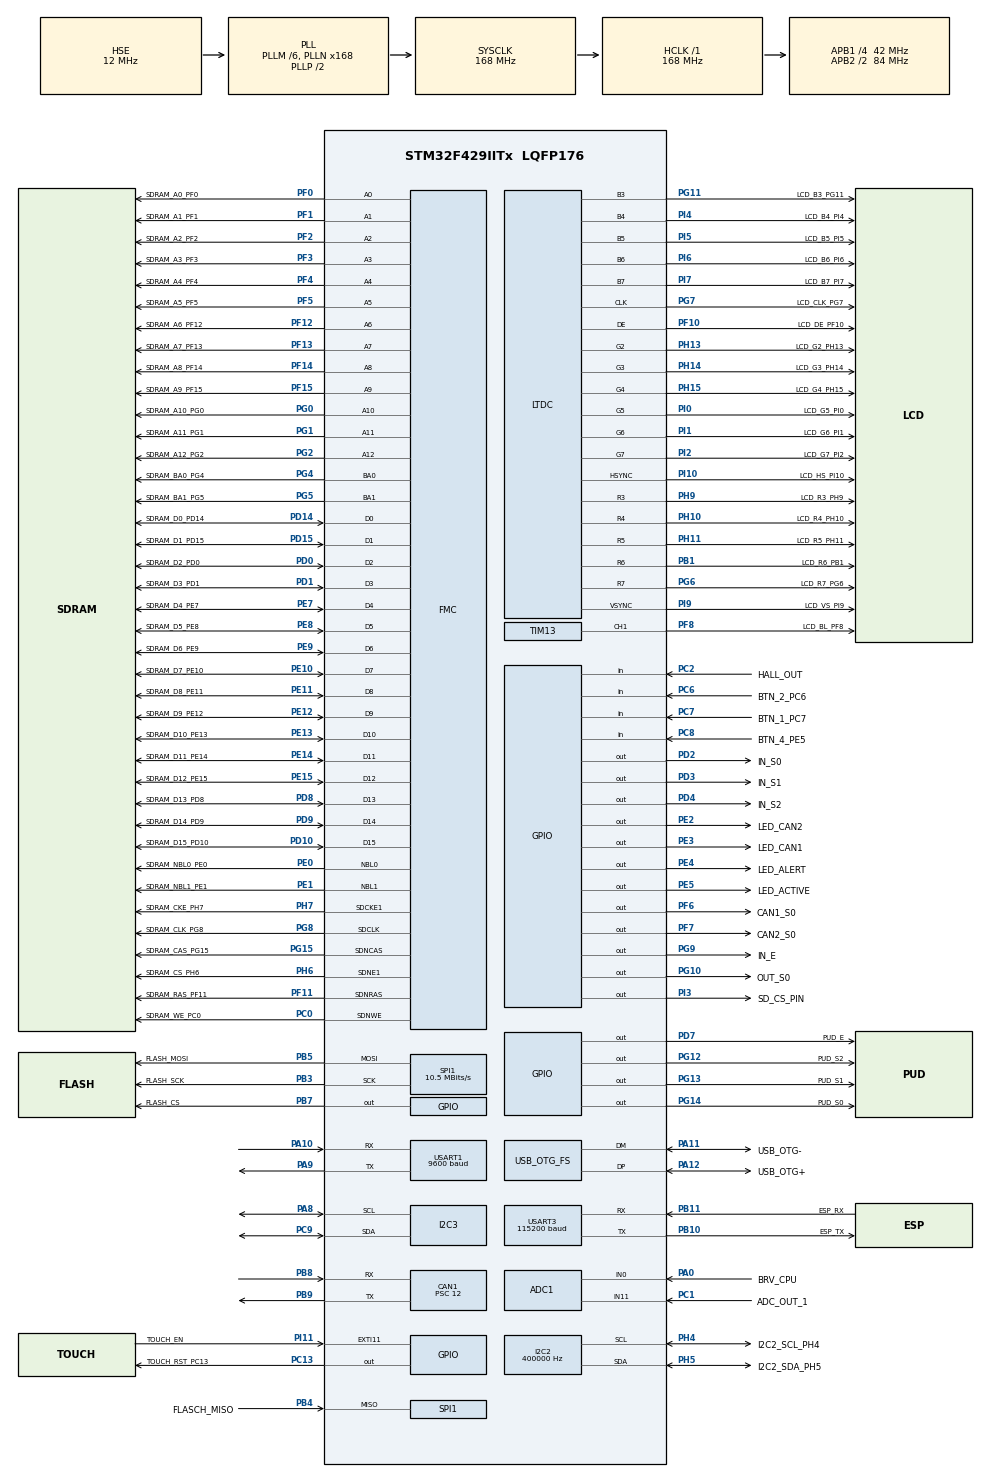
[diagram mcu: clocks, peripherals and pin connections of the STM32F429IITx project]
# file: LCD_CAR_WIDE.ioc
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ADC1.Channel-0\#ChannelRegularConversion=ADC_CHANNEL_11
ADC1.NbrOfConversionFlag=1
ADC1.Rank-0\#ChannelRegularConversion=1
ADC1.SamplingTime-0\#ChannelRegularConversion=ADC_SAMPLETIME_3CYCLES
ADC1.master=1
CAN1.BS1=CAN_BS1_4TQ
CAN1.BS2=CAN_BS2_2TQ
CAN1.CalculateBaudRate=500000
CAN1.CalculateTimeBit=2000
CAN1.CalculateTimeQuantum=285.7142857142857
CAN1.Prescaler=12
DMA2D.ColorMode=DMA2D_OUTPUT_RGB565
DMA2D.Mode=DMA2D_M2M
Dma.Request0=USART3_RX
Dma.Request1=USART3_TX
Dma.USART3_RX.0.Direction=DMA_PERIPH_TO_MEMORY
Dma.USART3_RX.0.FIFOMode=DMA_FIFOMODE_DISABLE
Dma.USART3_RX.0.Instance=DMA1_Stream1
Dma.USART3_RX.0.MemDataAlignment=DMA_MDATAALIGN_BYTE
Dma.USART3_RX.0.MemInc=DMA_MINC_ENABLE
Dma.USART3_RX.0.Mode=DMA_NORMAL
Dma.USART3_RX.0.PeriphDataAlignment=DMA_PDATAALIGN_BYTE
Dma.USART3_RX.0.PeriphInc=DMA_PINC_DISABLE
Dma.USART3_RX.0.Priority=DMA_PRIORITY_LOW
Dma.USART3_TX.1.Direction=DMA_MEMORY_TO_PERIPH
Dma.USART3_TX.1.FIFOMode=DMA_FIFOMODE_DISABLE
Dma.USART3_TX.1.Instance=DMA1_Stream3
Dma.USART3_TX.1.MemDataAlignment=DMA_MDATAALIGN_BYTE
Dma.USART3_TX.1.MemInc=DMA_MINC_ENABLE
Dma.USART3_TX.1.Mode=DMA_NORMAL
Dma.USART3_TX.1.PeriphDataAlignment=DMA_PDATAALIGN_BYTE
Dma.USART3_TX.1.PeriphInc=DMA_PINC_DISABLE
Dma.USART3_TX.1.Priority=DMA_PRIORITY_LOW
FMC.CASLatency1=FMC_SDRAM_CAS_LATENCY_3
FMC.ColumnBitsNumber1=FMC_SDRAM_COLUMN_BITS_NUM_9
FMC.ExitSelfRefreshDelay1=8
FMC.LoadToActiveDelay1=2
FMC.RCDDelay1=2
FMC.RPDelay1=2
FMC.RPDelay2=2
FMC.ReadBurst1=FMC_SDRAM_RBURST_ENABLE
FMC.ReadPipeDelay1=FMC_SDRAM_RPIPE_DELAY_1
FMC.ReadPipeDelay2=FMC_SDRAM_RPIPE_DELAY_1
FMC.RowCycleDelay1=7
FMC.RowCycleDelay2=7
FMC.SDClockPeriod1=FMC_SDRAM_CLOCK_PERIOD_2
FMC.SDClockPeriod2=FMC_SDRAM_CLOCK_PERIOD_2
FMC.SelfRefreshTime1=4
FMC.WriteRecoveryTime1=5
FREERTOS.Queues01=jsonQueue,6,512,1,Dynamic,NULL,NULL
FREERTOS.Tasks01=START_Task,24,128,Start_START_Task,Default,NULL,Dynamic,NULL,NULL;TouchGFXTask,40,4096,TouchGFX_Task,As weak,NULL,Dynamic,NULL,NULL;BRIGHTNESS_Task,8,1024,Start_BRIGHTNESS_Task,Default,NULL,Dynamic,NULL,NULL;nmea,8,1024,Start_nmea,Default,NULL,Dynamic,NULL,NULL;Ind_OIL,8,128,Start_OIL,Default,NULL,Dynamic,NULL,NULL;Ind_FUEL,8,128,Start_Ind_FUEL,Default,NULL,Dynamic,NULL,NULL;Ind_BATT,8,128,Start_IndBATT,Default,NULL,Dynamic,NULL,NULL;Ind_ECT,8,128,Start_Ind_ECT,Default,NULL,Dynamic,NULL,NULL;other,8,128,Start_other,Default,NULL,Dynamic,NULL,NULL;RPM_10,8,4096,Start_RMP_10,Default,&rpmWindowSize,Dynamic,NULL,NULL;FUELUSED_11,8,4096,Start_FUELUSED_11,Default,&windows,Dynamic,NULL,NULL;UART_Task,8,4096,Start_UART_Task,Default,NULL,Dynamic,NULL,NULL;MotohoursTask,8,1024,Start_MotohoursTask,Default,NULL,Dynamic,NULL,NULL;Button_R_Task,8,1024,Start_R_Buttan_Task14,Default,NULL,Dynamic,NULL,NULL;Button_L_Task,8,1024,Start_Buttan_L_Task,Default,NULL,Dynamic,NULL,NULL;JSON_Parse_Task,8,1024,Start_JSON_Parse_Task,Default,NULL,Dynamic,NULL,NULL
FREERTOS.configASSERT(\ x\ )=if ((x) \=\= 0) {taskDISABLE_INTERRUPTS(); for( ;; );} 
FREERTOS.configMINIMAL_STACK_SIZE=128
FREERTOS.configPRIO_BITS=4
FREERTOS.configTIMER_QUEUE_LENGTH=10
FREERTOS.configTOTAL_HEAP_SIZE=140360
FREERTOS.configUSE_NEWLIB_REENTRANT=1
I2C2.AddressingMode=I2C_ADDRESSINGMODE_7BIT
I2C2.ClockSpeed=400000
I2C2.GeneralCallMode=I2C_GENERALCALL_DISABLE
I2C2.I2C_Mode=I2C_Fast
I2C2.OwnAddress=26
LTDC.ActiveH=1280
LTDC.ActiveW=480
LTDC.Alpha_L0=255
LTDC.Alpha_L1=255
LTDC.BlendingFactor1_L0=LTDC_BLENDING_FACTOR1_PAxCA
LTDC.BlendingFactor1_L1=LTDC_BLENDING_FACTOR1_PAxCA
LTDC.BlendingFactor2_L0=LTDC_BLENDING_FACTOR2_PAxCA
LTDC.BlendingFactor2_L1=LTDC_BLENDING_FACTOR2_PAxCA
LTDC.Blue_L0=0
LTDC.DEPolarity=LTDC_DEPOLARITY_AL
LTDC.FBStartAdress_L0=0xD0000000
LTDC.FBStartAdress_L1=0xD012C000
LTDC.Green=0
LTDC.Green_L0=0
LTDC.HBP=12
LTDC.HFP=12
LTDC.HSPolarity=LTDC_HSPOLARITY_AH
LTDC.HSync=6
LTDC.ImageHeight_L0=1280
LTDC.ImageHeight_L1=1280
LTDC.ImageWidth_L0=480
LTDC.ImageWidth_L1=480
LTDC.Layers=0
LTDC.PCPolarity=LTDC_PCPOLARITY_IIPC
LTDC.PixelFormat_L0=LTDC_PIXEL_FORMAT_RGB565
LTDC.Red=0
LTDC.VBP=30
LTDC.VFP=15
LTDC.VSPolarity=LTDC_VSPOLARITY_AH
LTDC.VSync=15
LTDC.WindowX0_L0=0
LTDC.WindowX1_L0=480
LTDC.WindowX1_L1=480
LTDC.WindowY0_L0=0
LTDC.WindowY1_L0=1280
LTDC.WindowY1_L1=1280
Mcu.Family=STM32F4
Mcu.Name=STM32F429IITx
Mcu.Package=LQFP176
NVIC.CAN1_RX0_IRQn=true\:5\:0\:false\:false\:true\:true\:true\:true\:true
NVIC.DMA1_Stream1_IRQn=true\:5\:0\:false\:false\:true\:true\:false\:true\:true
NVIC.DMA1_Stream3_IRQn=true\:5\:0\:false\:false\:true\:true\:false\:true\:true
NVIC.DMA2D_IRQn=true\:5\:0\:false\:false\:true\:true\:true\:true\:true
NVIC.EXTI15_10_IRQn=true\:5\:0\:false\:false\:true\:true\:true\:true\:true
NVIC.FMC_IRQn=true\:5\:0\:false\:false\:true\:true\:true\:true\:true
NVIC.LTDC_IRQn=true\:5\:0\:false\:false\:true\:true\:true\:true\:true
NVIC.OTG_FS_IRQn=true\:5\:0\:false\:false\:true\:true\:false\:true\:true
NVIC.PriorityGroup=NVIC_PRIORITYGROUP_4
NVIC.TIM6_DAC_IRQn=true\:15\:0\:false\:false\:true\:false\:false\:true\:true
NVIC.TimeBase=TIM6_DAC_IRQn
NVIC.TimeBaseIP=TIM6
NVIC.USART1_IRQn=true\:5\:0\:false\:false\:true\:true\:true\:true\:true
NVIC.USART3_IRQn=true\:5\:0\:false\:false\:true\:true\:true\:true\:true
PA0/WKUP.GPIO_Label=BRV_CPU
PA0/WKUP.Signal=ADCx_IN0
PA10.Mode=Asynchronous
PA10.Signal=USART1_RX
PA11.GPIO_Label=USB_OTG-
PA11.Mode=Device_Only
PA11.Signal=USB_OTG_FS_DM
PA12.GPIO_Label=USB_OTG+
PA12.Mode=Device_Only
PA12.Signal=USB_OTG_FS_DP
PA13.GPIO_Label=SWDIO
PA13.Mode=Serial_Wire
PA13.Signal=SYS_JTMS-SWDIO
PA14.GPIO_Label=SWCLK
PA14.Mode=Serial_Wire
PA14.Signal=SYS_JTCK-SWCLK
PA8.Mode=I2C
PA8.Signal=I2C3_SCL
PA9.Mode=Asynchronous
PA9.Signal=USART1_TX
PB1.GPIO_Label=LCD_R6_PB1
PB1.GPIO_Mode=GPIO_MODE_AF_PP
PB1.GPIO_PuPd=GPIO_PULLUP
PB1.GPIO_Speed=GPIO_SPEED_FREQ_VERY_HIGH
PB1.Mode=RGB565
PB1.Signal=LTDC_R6
PB10.GPIO_Label=ESP_TX
PB10.Mode=Asynchronous
PB10.Signal=USART3_TX
PB11.GPIO_Label=ESP_RX
PB11.Mode=Asynchronous
PB11.Signal=USART3_RX
PB12.GPIO_PuPd=GPIO_NOPULL
PB12.Signal=CAN2_RX
PB13.Signal=CAN2_TX
PB3.GPIO_Label=FLASH_SCK
PB3.Mode=Full_Duplex_Master
PB3.Signal=SPI1_SCK
PB4.GPIO_Label=FLASCH_MISO
PB4.Mode=Full_Duplex_Master
PB4.Signal=SPI1_MISO
PB5.GPIO_Label=FLASH_MOSI
PB5.Mode=Full_Duplex_Master
PB5.Signal=SPI1_MOSI
PB7.GPIO_Label=FLASH_CS
PB7.GPIO_Speed=GPIO_SPEED_FREQ_HIGH
PB7.PinState=GPIO_PIN_SET
PB7.Signal=GPIO_Output
PB8.GPIO_PuPd=GPIO_PULLDOWN
PB8.Mode=CAN_Activate
PB8.Signal=CAN1_RX
PB9.Mode=CAN_Activate
PB9.Signal=CAN1_TX
PC0.GPIO_Label=SDRAM_WE_PC0
PC0.Signal=FMC_SDNWE
PC1.GPIO_Label=ADC_OUT_1
PC1.Signal=ADCx_IN11
PC10.Signal=SPI3_SCK
PC11.Signal=SPI3_MISO
PC12.Signal=SPI3_MOSI
PC13.GPIO_Label=TOUCH_RST_PC13
PC13.PinState=GPIO_PIN_SET
PC13.Signal=GPIO_Output
PC2.GPIO_Label=HALL_OUT
PC2.Signal=GPIO_Input
PC6.GPIO_Label=BTN_2_PC6
PC6.Signal=GPIO_Input
PC7.GPIO_Label=BTN_1_PC7
PC7.Signal=GPIO_Input
PC8.GPIO_Label=BTN_4_PE5
PC8.Signal=GPIO_Input
PC9.Mode=I2C
PC9.Signal=I2C3_SDA
PD0.GPIO_Label=SDRAM_D2_PD0
PD0.Signal=FMC_D2_DA2
PD1.GPIO_Label=SDRAM_D3_PD1
PD1.Signal=FMC_D3_DA3
PD10.GPIO_Label=SDRAM_D15_PD10
PD10.Signal=FMC_D15_DA15
PD14.GPIO_Label=SDRAM_D0_PD14
PD14.Signal=FMC_D0_DA0
PD15.GPIO_Label=SDRAM_D1_PD15
PD15.Signal=FMC_D1_DA1
PD2.GPIO_Label=IN_S0
PD2.Signal=GPIO_Output
PD3.GPIO_Label=IN_S1
PD3.Signal=GPIO_Output
PD4.GPIO_Label=IN_S2
PD4.Signal=GPIO_Output
PD6.Signal=LTDC_B2
PD7.GPIO_Label=PUD_E
PD7.Signal=GPIO_Output
PD8.GPIO_Label=SDRAM_D13_PD8
PD8.Signal=FMC_D13_DA13
PD9.GPIO_Label=SDRAM_D14_PD9
PD9.Signal=FMC_D14_DA14
PE0.GPIO_Label=SDRAM_NBL0_PE0
PE0.Signal=FMC_NBL0
PE1.GPIO_Label=SDRAM_NBL1_PE1
PE1.Signal=FMC_NBL1
PE10.GPIO_Label=SDRAM_D7_PE10
PE10.Signal=FMC_D7_DA7
PE11.GPIO_Label=SDRAM_D8_PE11
PE11.Signal=FMC_D8_DA8
PE12.GPIO_Label=SDRAM_D9_PE12
PE12.Signal=FMC_D9_DA9
PE13.GPIO_Label=SDRAM_D10_PE13
PE13.Signal=FMC_D10_DA10
PE14.GPIO_Label=SDRAM_D11_PE14
PE14.Signal=FMC_D11_DA11
PE15.GPIO_Label=SDRAM_D12_PE15
PE15.Signal=FMC_D12_DA12
PE2.GPIO_Label=LED_CAN2
PE2.Signal=GPIO_Output
PE3.GPIO_Label=LED_CAN1
PE3.Signal=GPIO_Output
PE4.GPIO_Label=LED_ALERT
PE4.Signal=GPIO_Output
PE5.GPIO_Label=LED_ACTIVE
PE5.Signal=GPIO_Output
PE7.GPIO_Label=SDRAM_D4_PE7
PE7.Signal=FMC_D4_DA4
PE8.GPIO_Label=SDRAM_D5_PE8
PE8.Signal=FMC_D5_DA5
PE9.GPIO_Label=SDRAM_D6_PE9
PE9.Signal=FMC_D6_DA6
PF0.GPIO_Label=SDRAM_A0_PF0
PF0.Signal=FMC_A0
PF1.GPIO_Label=SDRAM_A1_PF1
PF1.Signal=FMC_A1
PF10.GPIO_Label=LCD_DE_PF10
PF10.GPIO_Mode=GPIO_MODE_AF_PP
PF10.GPIO_PuPd=GPIO_PULLUP
PF10.GPIO_Speed=GPIO_SPEED_FREQ_VERY_HIGH
PF10.Mode=RGB565
PF10.Signal=LTDC_DE
PF11.GPIO_Label=SDRAM_RAS_PF11
PF11.Signal=FMC_SDNRAS
PF12.GPIO_Label=SDRAM_A6_PF12
PF12.Signal=FMC_A6
PF13.GPIO_Label=SDRAM_A7_PF13
PF13.Signal=FMC_A7
PF14.GPIO_Label=SDRAM_A8_PF14
PF14.Signal=FMC_A8
PF15.GPIO_Label=SDRAM_A9_PF15
PF15.Signal=FMC_A9
PF2.GPIO_Label=SDRAM_A2_PF2
PF2.Signal=FMC_A2
PF3.GPIO_Label=SDRAM_A3_PF3
PF3.Signal=FMC_A3
PF4.GPIO_Label=SDRAM_A4_PF4
PF4.Signal=FMC_A4
PF5.GPIO_Label=SDRAM_A5_PF5
PF5.Signal=FMC_A5
PF6.GPIO_Label=CAN1_S0
PF6.GPIO_ModeDefaultOutputPP=GPIO_MODE_OUTPUT_PP
PF6.GPIO_PuPd=GPIO_PULLUP
PF6.GPIO_Speed=GPIO_SPEED_FREQ_VERY_HIGH
PF6.PinState=GPIO_PIN_SET
PF6.Signal=GPIO_Output
PF7.GPIO_Label=CAN2_S0
PF7.GPIO_ModeDefaultOutputPP=GPIO_MODE_OUTPUT_PP
PF7.GPIO_PuPd=GPIO_PULLUP
PF7.GPIO_Speed=GPIO_SPEED_FREQ_VERY_HIGH
PF7.PinState=GPIO_PIN_SET
PF7.Signal=GPIO_Output
PF8.GPIO_Label=LCD_BL_PF8
PF8.Signal=S_TIM13_CH1
PG0.GPIO_Label=SDRAM_A10_PG0
PG0.Signal=FMC_A10
PG1.GPIO_Label=SDRAM_A11_PG1
PG1.Signal=FMC_A11
PG10.GPIO_Label=OUT_S0
PG10.Signal=GPIO_Output
PG11.GPIO_Label=LCD_B3_PG11
PG11.GPIO_Mode=GPIO_MODE_AF_PP
PG11.GPIO_PuPd=GPIO_PULLUP
PG11.GPIO_Speed=GPIO_SPEED_FREQ_VERY_HIGH
PG11.Mode=RGB565
PG11.Signal=LTDC_B3
PG12.GPIO_Label=PUD_S2
PG12.Signal=GPIO_Output
PG13.GPIO_Label=PUD_S1
PG13.Signal=GPIO_Output
PG14.GPIO_Label=PUD_S0
PG14.Signal=GPIO_Output
PG15.GPIO_Label=SDRAM_CAS_PG15
PG15.Signal=FMC_SDNCAS
PG2.GPIO_Label=SDRAM_A12_PG2
PG2.Signal=FMC_A12
PG4.GPIO_Label=SDRAM_BA0_PG4
PG4.Signal=FMC_A14_BA0
PG5.GPIO_Label=SDRAM_BA1_PG5
PG5.Signal=FMC_A15_BA1
PG6.GPIO_Label=LCD_R7_PG6
PG6.GPIO_Mode=GPIO_MODE_AF_PP
PG6.GPIO_PuPd=GPIO_PULLUP
PG6.GPIO_Speed=GPIO_SPEED_FREQ_VERY_HIGH
PG6.Mode=RGB565
PG6.Signal=LTDC_R7
PG7.GPIO_Label=LCD_CLK_PG7
PG7.GPIO_Mode=GPIO_MODE_AF_PP
PG7.GPIO_PuPd=GPIO_PULLUP
PG7.GPIO_Speed=GPIO_SPEED_FREQ_VERY_HIGH
PG7.Mode=RGB565
PG7.Signal=LTDC_CLK
PG8.GPIO_Label=SDRAM_CLK_PG8
PG8.Signal=FMC_SDCLK
PG9.GPIO_Label=IN_E
PG9.Signal=GPIO_Output
PH0/OSC_IN.GPIO_Label=OSC_IN
PH0/OSC_IN.Mode=HSE-External-Oscillator
PH0/OSC_IN.Signal=RCC_OSC_IN
PH1/OSC_OUT.GPIO_Label=OSC_OUT
PH1/OSC_OUT.Mode=HSE-External-Oscillator
PH1/OSC_OUT.Signal=RCC_OSC_OUT
PH10.GPIO_Label=LCD_R4_PH10
PH10.GPIO_Mode=GPIO_MODE_AF_PP
PH10.GPIO_PuPd=GPIO_PULLUP
PH10.GPIO_Speed=GPIO_SPEED_FREQ_VERY_HIGH
PH10.Mode=RGB565
PH10.Signal=LTDC_R4
PH11.GPIO_Label=LCD_R5_PH11
PH11.GPIO_Mode=GPIO_MODE_AF_PP
PH11.GPIO_PuPd=GPIO_PULLUP
PH11.GPIO_Speed=GPIO_SPEED_FREQ_VERY_HIGH
PH11.Mode=RGB565
PH11.Signal=LTDC_R5
PH13.GPIO_Label=LCD_G2_PH13
PH13.GPIO_Mode=GPIO_MODE_AF_PP
PH13.GPIO_PuPd=GPIO_PULLUP
PH13.GPIO_Speed=GPIO_SPEED_FREQ_VERY_HIGH
PH13.Mode=RGB565
PH13.Signal=LTDC_G2
PH14.GPIO_Label=LCD_G3_PH14
PH14.GPIO_Mode=GPIO_MODE_AF_PP
PH14.GPIO_PuPd=GPIO_PULLUP
PH14.GPIO_Speed=GPIO_SPEED_FREQ_VERY_HIGH
PH14.Mode=RGB565
PH14.Signal=LTDC_G3
PH15.GPIO_Label=LCD_G4_PH15
PH15.GPIO_Mode=GPIO_MODE_AF_PP
PH15.GPIO_PuPd=GPIO_PULLUP
PH15.GPIO_Speed=GPIO_SPEED_FREQ_VERY_HIGH
PH15.Mode=RGB565
PH15.Signal=LTDC_G4
PH4.GPIO_Label=I2C2_SCL_PH4
PH4.Mode=I2C
PH4.Signal=I2C2_SCL
PH5.GPIO_Label=I2C2_SDA_PH5
PH5.Mode=I2C
PH5.Signal=I2C2_SDA
PH6.GPIO_Label=SDRAM_CS_PH6
PH6.Mode=SdramChipSelect2_1
PH6.Signal=FMC_SDNE1
PH7.GPIO_Label=SDRAM_CKE_PH7
PH7.Mode=SdramChipSelect2_1
PH7.Signal=FMC_SDCKE1
PH8.GPIO_Label=LCD_R2_PH8
PH8.Signal=LTDC_R2
PH9.GPIO_Label=LCD_R3_PH9
PH9.GPIO_Mode=GPIO_MODE_AF_PP
PH9.GPIO_PuPd=GPIO_PULLUP
PH9.GPIO_Speed=GPIO_SPEED_FREQ_VERY_HIGH
PH9.Mode=RGB565
PH9.Signal=LTDC_R3
PI0.GPIO_Label=LCD_G5_PI0
PI0.GPIO_Mode=GPIO_MODE_AF_PP
PI0.GPIO_PuPd=GPIO_PULLUP
PI0.GPIO_Speed=GPIO_SPEED_FREQ_VERY_HIGH
PI0.Mode=RGB565
PI0.Signal=LTDC_G5
PI1.GPIO_Label=LCD_G6_PI1
PI1.GPIO_Mode=GPIO_MODE_AF_PP
PI1.GPIO_PuPd=GPIO_PULLUP
PI1.GPIO_Speed=GPIO_SPEED_FREQ_VERY_HIGH
PI1.Mode=RGB565
PI1.Signal=LTDC_G6
PI10.GPIO_Label=LCD_HS_PI10
PI10.GPIO_Mode=GPIO_MODE_AF_PP
PI10.GPIO_PuPd=GPIO_PULLUP
PI10.GPIO_Speed=GPIO_SPEED_FREQ_VERY_HIGH
PI10.Mode=RGB565
PI10.Signal=LTDC_HSYNC
PI11.GPIO_Label=TOUCH_EN
PI11.GPIO_ModeDefaultEXTI=GPIO_MODE_IT_RISING
PI11.GPIO_PuPd=GPIO_PULLUP
PI11.Signal=GPXTI11
PI2.GPIO_Label=LCD_G7_PI2
PI2.GPIO_Mode=GPIO_MODE_AF_PP
PI2.GPIO_PuPd=GPIO_PULLUP
PI2.GPIO_Speed=GPIO_SPEED_FREQ_VERY_HIGH
PI2.Mode=RGB565
PI2.Signal=LTDC_G7
PI3.GPIO_Label=SD_CS_PIN
PI3.Signal=GPIO_Output
PI4.GPIO_Label=LCD_B4_PI4
PI4.GPIO_Mode=GPIO_MODE_AF_PP
PI4.GPIO_PuPd=GPIO_PULLUP
PI4.GPIO_Speed=GPIO_SPEED_FREQ_VERY_HIGH
PI4.Mode=RGB565
PI4.Signal=LTDC_B4
PI5.GPIO_Label=LCD_B5_PI5
PI5.GPIO_Mode=GPIO_MODE_AF_PP
PI5.GPIO_PuPd=GPIO_PULLUP
PI5.GPIO_Speed=GPIO_SPEED_FREQ_VERY_HIGH
PI5.Mode=RGB565
PI5.Signal=LTDC_B5
PI6.GPIO_Label=LCD_B6_PI6
PI6.GPIO_Mode=GPIO_MODE_AF_PP
PI6.GPIO_PuPd=GPIO_PULLUP
PI6.GPIO_Speed=GPIO_SPEED_FREQ_VERY_HIGH
PI6.Mode=RGB565
PI6.Signal=LTDC_B6
PI7.GPIO_Label=LCD_B7_PI7
PI7.GPIO_Mode=GPIO_MODE_AF_PP
PI7.GPIO_PuPd=GPIO_PULLUP
PI7.GPIO_Speed=GPIO_SPEED_FREQ_VERY_HIGH
PI7.Mode=RGB565
PI7.Signal=LTDC_B7
PI9.GPIO_Label=LCD_VS_PI9
PI9.GPIO_Mode=GPIO_MODE_AF_PP
PI9.GPIO_PuPd=GPIO_PULLUP
PI9.GPIO_Speed=GPIO_SPEED_FREQ_VERY_HIGH
PI9.Mode=RGB565
PI9.Signal=LTDC_VSYNC
ProjectManager.HeapSize=0x400
ProjectManager.StackSize=0x800
ProjectManager.TargetToolchain=STM32CubeIDE
RCC.48MHZClocksFreq_Value=48000000
RCC.AHBFreq_Value=168000000
RCC.APB1CLKDivider=RCC_HCLK_DIV4
RCC.APB1Freq_Value=42000000
RCC.APB1TimFreq_Value=84000000
RCC.APB2CLKDivider=RCC_HCLK_DIV2
RCC.APB2Freq_Value=84000000
RCC.APB2TimFreq_Value=168000000
RCC.CortexFreq_Value=168000000
RCC.EXTERNAL_CLOCK_VALUE=12288000
RCC.FLatency-AdvancedSettings=FLASH_LATENCY_5
RCC.HCLKFreq_Value=168000000
RCC.HSEUsed=1
RCC.HSE_VALUE=12000000
RCC.HSI_VALUE=16000000
RCC.I2SClockSource=I2S_CLOCK_PLL
RCC.LSEUsed=0
RCC.LSE_VALUE=32768
RCC.LSIUsed=0
RCC.PLLM=6
RCC.PLLN=168
RCC.PLLQ=7
RCC.PLLSAIN=52
RCC.PLLUsed=1
RCC.SAIClockSource_BlockA=SAI_CLKSOURCE_PLLSAI
RCC.SAIClockSource_BlockB=SAI_CLKSOURCE_PLLSAI
RCC.SYSCLKFreq_VALUE=168000000
RCC.SYSCLKSource=RCC_SYSCLKSOURCE_PLLCLK
RCC.VCOOutputFreq_Value=336000000
SH.ADCx_IN0.0=ADC1_IN0,IN0
SH.ADCx_IN11.0=ADC1_IN11,IN11
SH.FMC_A0.0=FMC_A0,13b-sda1
SH.FMC_A1.0=FMC_A1,13b-sda1
SH.FMC_A10.0=FMC_A10,13b-sda1
SH.FMC_A11.0=FMC_A11,13b-sda1
SH.FMC_A12.0=FMC_A12,13b-sda1
SH.FMC_A14_BA0.0=FMC_BA0,FourSdramBanks1
SH.FMC_A15_BA1.0=FMC_BA1,FourSdramBanks1
SH.FMC_A2.0=FMC_A2,13b-sda1
SH.FMC_A3.0=FMC_A3,13b-sda1
SH.FMC_A4.0=FMC_A4,13b-sda1
SH.FMC_A5.0=FMC_A5,13b-sda1
SH.FMC_A6.0=FMC_A6,13b-sda1
SH.FMC_A7.0=FMC_A7,13b-sda1
SH.FMC_A8.0=FMC_A8,13b-sda1
SH.FMC_A9.0=FMC_A9,13b-sda1
SH.FMC_D0_DA0.0=FMC_D0,sd-16b-d1
SH.FMC_D10_DA10.0=FMC_D10,sd-16b-d1
SH.FMC_D11_DA11.0=FMC_D11,sd-16b-d1
SH.FMC_D12_DA12.0=FMC_D12,sd-16b-d1
SH.FMC_D13_DA13.0=FMC_D13,sd-16b-d1
SH.FMC_D14_DA14.0=FMC_D14,sd-16b-d1
SH.FMC_D15_DA15.0=FMC_D15,sd-16b-d1
SH.FMC_D1_DA1.0=FMC_D1,sd-16b-d1
SH.FMC_D2_DA2.0=FMC_D2,sd-16b-d1
SH.FMC_D3_DA3.0=FMC_D3,sd-16b-d1
SH.FMC_D4_DA4.0=FMC_D4,sd-16b-d1
SH.FMC_D5_DA5.0=FMC_D5,sd-16b-d1
SH.FMC_D6_DA6.0=FMC_D6,sd-16b-d1
SH.FMC_D7_DA7.0=FMC_D7,sd-16b-d1
SH.FMC_D8_DA8.0=FMC_D8,sd-16b-d1
SH.FMC_D9_DA9.0=FMC_D9,sd-16b-d1
SH.FMC_NBL0.0=FMC_NBL0,Sd2ByteEnable1
SH.FMC_NBL1.0=FMC_NBL1,Sd2ByteEnable1
SH.FMC_SDCLK.0=FMC_SDCLK,13b-sda1
SH.FMC_SDNCAS.0=FMC_SDNCAS,13b-sda1
SH.FMC_SDNRAS.0=FMC_SDNRAS,13b-sda1
SH.FMC_SDNWE.0=FMC_SDNWE,13b-sda1
SH.S_TIM13_CH1.0=TIM13_CH1,PWM Generation1 CH1
SPI1.BaudRatePrescaler=SPI_BAUDRATEPRESCALER_8
SPI1.CalculateBaudRate=10.5 MBits/s
SPI1.Direction=SPI_DIRECTION_2LINES
SPI1.FirstBit=SPI_FIRSTBIT_MSB
SPI1.Mode=SPI_MODE_MASTER
SPI1.VirtualType=VM_MASTER
STMicroelectronics.X-CUBE-TOUCHGFX.4.22.0.ApplicationCcGraphicsJjApplication=TouchGFXOoGenerator
STMicroelectronics.X-CUBE-TOUCHGFX.4.22.0.tgfx_address1=0xD0000000
STMicroelectronics.X-CUBE-TOUCHGFX.4.22.0.tgfx_address2=0xD012C000
STMicroelectronics.X-CUBE-TOUCHGFX.4.22.0.tgfx_buffering_strategy=Double
STMicroelectronics.X-CUBE-TOUCHGFX.4.22.0.tgfx_datareader_mem_base_address=0x90000000
STMicroelectronics.X-CUBE-TOUCHGFX.4.22.0.tgfx_datareader_mem_size=0x400000
STMicroelectronics.X-CUBE-TOUCHGFX.4.22.0.tgfx_display_interface=disp_ltdc
STMicroelectronics.X-CUBE-TOUCHGFX.4.22.0.tgfx_hardware_accelerator=dma_2d
STMicroelectronics.X-CUBE-TOUCHGFX.4.22.0.tgfx_location=By Address
STMicroelectronics.X-CUBE-TOUCHGFX.4.22.0.tgfx_vector_rendering=Disabled
STMicroelectronics.X-CUBE-TOUCHGFX.4.22.0.tgfx_vsync=vsync_ltdc
STMicroelectronics.X-CUBE-TOUCHGFX.4.22.0_IsPackSelfContextualization=true
TIM1.AutoReloadPreload=TIM_AUTORELOAD_PRELOAD_DISABLE
TIM1.Period=210
TIM13.AutoReloadPreload=TIM_AUTORELOAD_PRELOAD_ENABLE
TIM13.Channel=TIM_CHANNEL_1
TIM13.Period=1000-1
TIM13.Prescaler=90-1
USART1.BaudRate=9600
USART1.VirtualMode=VM_ASYNC
USART3.BaudRate=115200
USART3.VirtualMode=VM_ASYNC
USB_DEVICE.CLASS_NAME_FS=CDC
USB_DEVICE.PID_CDC_FS=57701
USB_DEVICE.PRODUCT_STRING_CDC_FS=OPF Dash
USB_DEVICE.VirtualMode-CDC_FS=Cdc
USB_DEVICE.VirtualModeFS=Cdc_FS
USB_OTG_FS.VirtualMode=Device_Only
VP_CRC_VS_CRC.Mode=CRC_Activate
VP_DMA2D_VS_DMA2D.Mode=DMA2D_Activate
VP_FREERTOS_VS_CMSIS_V2.Mode=CMSIS_V2
VP_STMicroelectronics.X-CUBE-TOUCHGFX_VS_GraphicsJjApplication_4.22.0.Mode=GraphicsJjApplication
VP_SYS_VS_tim6.Mode=TIM6
VP_TIM13_VS_ClockSourceINT.Mode=Enable_Timer
VP_TIM1_VS_ClockSourceINT.Mode=Internal
VP_USB_DEVICE_VS_USB_DEVICE_CDC_FS.Mode=CDC_FS
board=custom

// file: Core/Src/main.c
/* USER CODE BEGIN Header */
/**
 ******************************************************************************
 * @file           : main.c
 * @brief          : Main program body
 ******************************************************************************
 * @attention
 *
 * <h2><center>&copy; Copyright (c) 2021 STMicroelectronics.
 * All rights reserved.</center></h2>
 *
 * This software component is licensed by ST under BSD 3-Clause license,
 * the "License"; You may not use this file except in compliance with the
 * License. You may obtain a copy of the License at:
 *                        opensource.org/licenses/BSD-3-Clause
 *
 ******************************************************************************
 */
/* USER CODE END Header */
#include "main.h"
#include "cmsis_os.h"
#include "app_touchgfx.h"
#include "usb_device.h"

/* USER CODE BEGIN Includes */
//#include <File_Handling.h>
#include <stdio.h>
#include "Globals.h"
#include "extern.h"
#include "sdram.h"

#include "nmea.h"
#include "TargetTouch.h"
#include "Setup/Dash/setupDash.h"
#include "Setup/Field/setupField.h"

#include "eeprom24lc512.h"

#include <math.h>
#include "usart3_json_dma.h"
#include "cJSON.h"

#include"CAN.h"

//#include "z_flash_W25QXXX.h"
#include "level_tables.h"
#include "commands.h"
#include "data.h"
#include "json_dispatcher.h"
#include "W25Qxx.h"
/* USER CODE END Includes */

/* USER CODE BEGIN PTD */

osMessageQueueId_t jsonQueueHandle;
nmea_t gps;

/* USER CODE END PTD */

/* USER CODE BEGIN PD */
#define JSON_MSG_MAX_LEN 512
#define RPM_THRESHOLD 500
#define RPM_HYSTERESIS 10
/* USER CODE END PD */

/* USER CODE BEGIN PM */
//#define LCD_ORIENTATION_LANDSCAPE 0x01
/* USER CODE END PM */

ADC_HandleTypeDef hadc1;

CAN_HandleTypeDef hcan1;

CRC_HandleTypeDef hcrc;

DMA2D_HandleTypeDef hdma2d;

I2C_HandleTypeDef hi2c2;
I2C_HandleTypeDef hi2c3;

LTDC_HandleTypeDef hltdc;

SPI_HandleTypeDef hspi1;

TIM_HandleTypeDef htim1;
TIM_HandleTypeDef htim13;

UART_HandleTypeDef huart3;
DMA_HandleTypeDef hdma_usart3_rx;
DMA_HandleTypeDef hdma_usart3_tx;

SDRAM_HandleTypeDef hsdram1;

/* Definitions for START_Task */
osThreadId_t START_TaskHandle;
const osThreadAttr_t START_Task_attributes = {
  .name = "START_Task",
  .stack_size = 128 * 4,
  .priority = (osPriority_t) osPriorityNormal,
};
/* Definitions for TouchGFXTask */
osThreadId_t TouchGFXTaskHandle;
const osThreadAttr_t TouchGFXTask_attributes = {
  .name = "TouchGFXTask",
  .stack_size = 4096 * 4,
  .priority = (osPriority_t) osPriorityHigh,
};
/* Definitions for BRIGHTNESS_Task */
osThreadId_t BRIGHTNESS_TaskHandle;
const osThreadAttr_t BRIGHTNESS_Task_attributes = {
  .name = "BRIGHTNESS_Task",
  .stack_size = 1024 * 4,
  .priority = (osPriority_t) osPriorityLow,
};
/* Definitions for nmea */
osThreadId_t nmeaHandle;
const osThreadAttr_t nmea_attributes = {
  .name = "nmea",
  .stack_size = 1024 * 4,
  .priority = (osPriority_t) osPriorityLow,
};
/* Definitions for Ind_OIL */
osThreadId_t Ind_OILHandle;
const osThreadAttr_t Ind_OIL_attributes = {
  .name = "Ind_OIL",
  .stack_size = 128 * 4,
  .priority = (osPriority_t) osPriorityLow,
};
/* Definitions for Ind_FUEL */
osThreadId_t Ind_FUELHandle;
const osThreadAttr_t Ind_FUEL_attributes = {
  .name = "Ind_FUEL",
  .stack_size = 128 * 4,
  .priority = (osPriority_t) osPriorityLow,
};
/* Definitions for Ind_BATT */
osThreadId_t Ind_BATTHandle;
const osThreadAttr_t Ind_BATT_attributes = {
  .name = "Ind_BATT",
  .stack_size = 128 * 4,
  .priority = (osPriority_t) osPriorityLow,
};
/* Definitions for Ind_ECT */
osThreadId_t Ind_ECTHandle;
const osThreadAttr_t Ind_ECT_attributes = {
  .name = "Ind_ECT",
  .stack_size = 128 * 4,
  .priority = (osPriority_t) osPriorityLow,
};
/* Definitions for other */
osThreadId_t otherHandle;
const osThreadAttr_t other_attributes = {
  .name = "other",
  .stack_size = 128 * 4,
  .priority = (osPriority_t) osPriorityLow,
};
/* Definitions for RPM_10 */
osThreadId_t RPM_10Handle;
const osThreadAttr_t RPM_10_attributes = {
  .name = "RPM_10",
  .stack_size = 4096 * 4,
  .priority = (osPriority_t) osPriorityLow,
};
/* Definitions for FUELUSED_11 */
osThreadId_t FUELUSED_11Handle;
const osThreadAttr_t FUELUSED_11_attributes = {
  .name = "FUELUSED_11",
  .stack_size = 4096 * 4,
  .priority = (osPriority_t) osPriorityLow,
};
/* Definitions for UART_Task */
osThreadId_t UART_TaskHandle;
const osThreadAttr_t UART_Task_attributes = {
  .name = "UART_Task",
  .stack_size = 4096 * 4,
  .priority = (osPriority_t) osPriorityLow,
};
/* Definitions for MotohoursTask */
osThreadId_t MotohoursTaskHandle;
const osThreadAttr_t MotohoursTask_attributes = {
  .name = "MotohoursTask",
  .stack_size = 1024 * 4,
  .priority = (osPriority_t) osPriorityLow,
};
/* Definitions for Button_R_Task */
osThreadId_t Button_R_TaskHandle;
const osThreadAttr_t Button_R_Task_attributes = {
  .name = "Button_R_Task",
  .stack_size = 1024 * 4,
  .priority = (osPriority_t) osPriorityLow,
};
/* Definitions for Button_L_Task */
osThreadId_t Button_L_TaskHandle;
const osThreadAttr_t Button_L_Task_attributes = {
  .name = "Button_L_Task",
  .stack_size = 1024 * 4,
  .priority = (osPriority_t) osPriorityLow,
};
/* Definitions for JSON_Parse_Task */
osThreadId_t JSON_Parse_TaskHandle;
const osThreadAttr_t JSON_Parse_Task_attributes = {
  .name = "JSON_Parse_Task",
  .stack_size = 1024 * 4,
  .priority = (osPriority_t) osPriorityLow,
};
/* Definitions for jsonQueue */
osMessageQueueId_t jsonQueueHandle;
const osMessageQueueAttr_t jsonQueue_attributes = {
  .name = "jsonQueue"
};
/* USER CODE BEGIN PV */
FMC_SDRAM_CommandTypeDef command;

Statuses Current_Status;
FlagsUnion_t flags_union;
Flags_t device_flags;

CAN_TxHeaderTypeDef TxHeader;
CAN_RxHeaderTypeDef RxHeader;
uint8_t TxData[8];
uint8_t RxData[8];

uint8_t uartTransmitBufferSize;
uint8_t uartTransmitBuffer[128];

static char json_buf[JSON_MSG_MAX_LEN];

int rpmWindowSize = 10;     //  размер окна для RPM
int windows[2] = {10, 30};   //  0 fuelFlow  1

/* USER CODE END PV */

void SystemClock_Config(void);
static void MX_GPIO_Init(void);
static void MX_DMA_Init(void);
static void MX_LTDC_Init(void);
static void MX_DMA2D_Init(void);
static void MX_FMC_Init(void);
static void MX_CRC_Init(void);
static void MX_TIM13_Init(void);
static void MX_CAN1_Init(void);
static void MX_ADC1_Init(void);
static void MX_TIM1_Init(void);
static void MX_USART1_UART_Init(void);
static void MX_I2C2_Init(void);
static void MX_SPI1_Init(void);
static void MX_USART3_UART_Init(void);
static void MX_I2C3_Init(void);
void Start_START_Task(void *argument);
void TouchGFX_Task(void *argument);
void Start_BRIGHTNESS_Task(void *argument);
void Start_nmea(void *argument);
void Start_OIL(void *argument);
void Start_Ind_FUEL(void *argument);
void Start_IndBATT(void *argument);
void Start_Ind_ECT(void *argument);
void Start_other(void *argument);
void Start_RMP_10(void *argument);
void Start_FUELUSED_11(void *argument);
void Start_UART_Task(void *argument);
void Start_MotohoursTask(void *argument);
void Start_R_Buttan_Task14(void *argument);
void Start_Buttan_L_Task(void *argument);
void Start_JSON_Parse_Task(void *argument);

/* USER CODE BEGIN PFP */
Flags_t can_k;
EEPROM_Config_t eeprom_cfg;
void HAL_UART_TxCpltCallback();
void initAll(void);
bool LoadFlagsFromEEPROM(void);
void SaveFlagsToEEPROM(void);
void InitFlags(void);
void app_init_usart3(void);
/* USER CODE END PFP */

int main(void)
{

  /* MCU Configuration--------------------------------------------------------*/

  /* Reset of all peripherals, Initializes the Flash interface and the Systick. */
  HAL_Init();

  /* Configure the system clock */
  SystemClock_Config();

  /* Initialize all configured peripherals */
  MX_GPIO_Init();
  MX_DMA_Init();
  MX_LTDC_Init();
  MX_DMA2D_Init();
  MX_FMC_Init();
  MX_CRC_Init();
  MX_TIM13_Init();
  MX_CAN1_Init();
  MX_ADC1_Init();
  MX_TIM1_Init();
  MX_USART1_UART_Init();
  MX_I2C2_Init();
  MX_SPI1_Init();
  W25qxx_Init();
  MX_USART3_UART_Init();
  MX_I2C3_Init();
  MX_TouchGFX_Init();
  /* Call PreOsInit function */
  MX_TouchGFX_PreOSInit();
  /* USER CODE BEGIN 2 */
  // W25qxx_Init();
  InitFlags();
  EEPROM_Config_t eeprom_cfg = {
          .hi2c = &hi2c3,
          .hcrc = 0,
          .i2c_address = 0x50 << 1,
          .page_size = 128,
          .write_timeout = 100,
          .read_timeout = 50,
          .motohours_main_addr = 0x0000,
          .motohours_backup_addr = 0x0100,
          .flags_main_addr = 0x0200,
          .flags_backup_addr = 0x0300,
          .array_main_addr = 0x0400,
          .array_backup_addr = 0x0500
      };
  app_init_usart3();
  EEPROM_Init(&eeprom_cfg);
//  LoadFlagsFromEEPROM();
  initAll();

 // USART3_JSON_DMA_Init(115200);
  /* USER CODE END 2 */

  /* Init scheduler */
  osKernelInitialize();

  /* Create the queue(s) */
  /* creation of jsonQueue */
  jsonQueueHandle = osMessageQueueNew (6, 512, &jsonQueue_attributes);

  /* Create the thread(s) */
  /* creation of START_Task */
  START_TaskHandle = osThreadNew(Start_START_Task, NULL, &START_Task_attributes);

  /* creation of TouchGFXTask */
  TouchGFXTaskHandle = osThreadNew(TouchGFX_Task, NULL, &TouchGFXTask_attributes);

  /* creation of BRIGHTNESS_Task */
  BRIGHTNESS_TaskHandle = osThreadNew(Start_BRIGHTNESS_Task, NULL, &BRIGHTNESS_Task_attributes);

  /* creation of nmea */
  nmeaHandle = osThreadNew(Start_nmea, NULL, &nmea_attributes);

  /* creation of Ind_OIL */
  Ind_OILHandle = osThreadNew(Start_OIL, NULL, &Ind_OIL_attributes);

  /* creation of Ind_FUEL */
  Ind_FUELHandle = osThreadNew(Start_Ind_FUEL, NULL, &Ind_FUEL_attributes);

  /* creation of Ind_BATT */
  Ind_BATTHandle = osThreadNew(Start_IndBATT, NULL, &Ind_BATT_attributes);

  /* creation of Ind_ECT */
  Ind_ECTHandle = osThreadNew(Start_Ind_ECT, NULL, &Ind_ECT_attributes);

  /* creation of other */
  otherHandle = osThreadNew(Start_other, NULL, &other_attributes);

  /* creation of RPM_10 */
  RPM_10Handle = osThreadNew(Start_RMP_10, (void*) &rpmWindowSize, &RPM_10_attributes);

  /* creation of FUELUSED_11 */
  FUELUSED_11Handle = osThreadNew(Start_FUELUSED_11, (void*) &windows, &FUELUSED_11_attributes);

  /* creation of UART_Task */
  UART_TaskHandle = osThreadNew(Start_UART_Task, NULL, &UART_Task_attributes);

  /* creation of MotohoursTask */
  MotohoursTaskHandle = osThreadNew(Start_MotohoursTask, NULL, &MotohoursTask_attributes);

  /* creation of Button_R_Task */
  Button_R_TaskHandle = osThreadNew(Start_R_Buttan_Task14, NULL, &Button_R_Task_attributes);

  /* creation of Button_L_Task */
  Button_L_TaskHandle = osThreadNew(Start_Buttan_L_Task, NULL, &Button_L_Task_attributes);

  /* creation of JSON_Parse_Task */
  JSON_Parse_TaskHandle = osThreadNew(Start_JSON_Parse_Task, NULL, &JSON_Parse_Task_attributes);

  /* Start scheduler */
  osKernelStart();

  /* We should never get here as control is now taken by the scheduler */

  /* Infinite loop */
	while (1) {

	}
}

void SystemClock_Config(void)
{
  RCC_OscInitTypeDef RCC_OscInitStruct = {0};
  RCC_ClkInitTypeDef RCC_ClkInitStruct = {0};

  /** Configure the main internal regulator output voltage
  */
  __HAL_RCC_PWR_CLK_ENABLE();
  __HAL_PWR_VOLTAGESCALING_CONFIG(PWR_REGULATOR_VOLTAGE_SCALE1);

  /** Initializes the RCC Oscillators according to the specified parameters
  * in the RCC_OscInitTypeDef structure.
  */
  RCC_OscInitStruct.OscillatorType = RCC_OSCILLATORTYPE_HSE;
  RCC_OscInitStruct.HSEState = RCC_HSE_ON;
  RCC_OscInitStruct.PLL.PLLState = RCC_PLL_ON;
  RCC_OscInitStruct.PLL.PLLSource = RCC_PLLSOURCE_HSE;
  RCC_OscInitStruct.PLL.PLLM = 6;
  RCC_OscInitStruct.PLL.PLLN = 168;
  RCC_OscInitStruct.PLL.PLLP = RCC_PLLP_DIV2;
  RCC_OscInitStruct.PLL.PLLQ = 7;
  if (HAL_RCC_OscConfig(&RCC_OscInitStruct) != HAL_OK)
  {
    Error_Handler();
  }

  /** Initializes the CPU, AHB and APB buses clocks
  */
  RCC_ClkInitStruct.ClockType = RCC_CLOCKTYPE_HCLK|RCC_CLOCKTYPE_SYSCLK
                              |RCC_CLOCKTYPE_PCLK1|RCC_CLOCKTYPE_PCLK2;
  RCC_ClkInitStruct.SYSCLKSource = RCC_SYSCLKSOURCE_PLLCLK;
  RCC_ClkInitStruct.AHBCLKDivider = RCC_SYSCLK_DIV1;
  RCC_ClkInitStruct.APB1CLKDivider = RCC_HCLK_DIV4;
  RCC_ClkInitStruct.APB2CLKDivider = RCC_HCLK_DIV2;

  if (HAL_RCC_ClockConfig(&RCC_ClkInitStruct, FLASH_LATENCY_5) != HAL_OK)
  {
    Error_Handler();
  }
}

static void MX_ADC1_Init(void)
{

  ADC_ChannelConfTypeDef sConfig = {0};

  /** Configure the global features of the ADC (Clock, Resolution, Data Alignment and number of conversion)
  */
  hadc1.Instance = ADC1;
  hadc1.Init.ClockPrescaler = ADC_CLOCK_SYNC_PCLK_DIV4;
  hadc1.Init.Resolution = ADC_RESOLUTION_12B;
  hadc1.Init.ScanConvMode = DISABLE;
  hadc1.Init.ContinuousConvMode = DISABLE;
  hadc1.Init.DiscontinuousConvMode = DISABLE;
  hadc1.Init.ExternalTrigConvEdge = ADC_EXTERNALTRIGCONVEDGE_NONE;
  hadc1.Init.ExternalTrigConv = ADC_SOFTWARE_START;
  hadc1.Init.DataAlign = ADC_DATAALIGN_RIGHT;
  hadc1.Init.NbrOfConversion = 1;
  hadc1.Init.DMAContinuousRequests = DISABLE;
  hadc1.Init.EOCSelection = ADC_EOC_SINGLE_CONV;
  if (HAL_ADC_Init(&hadc1) != HAL_OK)
  {
    Error_Handler();
  }

  /** Configure for the selected ADC regular channel its corresponding rank in the sequencer and its sample time.
  */
  sConfig.Channel = ADC_CHANNEL_11;
  sConfig.Rank = 1;
  sConfig.SamplingTime = ADC_SAMPLETIME_3CYCLES;
  if (HAL_ADC_ConfigChannel(&hadc1, &sConfig) != HAL_OK)
  {
    Error_Handler();
  }

}

static void MX_CAN1_Init(void)
{

  /* USER CODE BEGIN CAN1_Init 0 */

	CAN_FilterTypeDef sFilterConfig; //declare CAN filter structure
  /* USER CODE END CAN1_Init 0 */

  hcan1.Instance = CAN1;
  hcan1.Init.Prescaler = 12;
  hcan1.Init.Mode = CAN_MODE_NORMAL;
  hcan1.Init.SyncJumpWidth = CAN_SJW_1TQ;
  hcan1.Init.TimeSeg1 = CAN_BS1_4TQ;
  hcan1.Init.TimeSeg2 = CAN_BS2_2TQ;
  hcan1.Init.TimeTriggeredMode = DISABLE;
  hcan1.Init.AutoBusOff = DISABLE;
  hcan1.Init.AutoWakeUp = DISABLE;
  hcan1.Init.AutoRetransmission = DISABLE;
  hcan1.Init.ReceiveFifoLocked = DISABLE;
  hcan1.Init.TransmitFifoPriority = DISABLE;
  if (HAL_CAN_Init(&hcan1) != HAL_OK)
  {
    Error_Handler();
  }
  /* USER CODE BEGIN CAN1_Init 2 */
	sFilterConfig.FilterBank = 15;
	sFilterConfig.FilterMode = CAN_FILTERMODE_IDMASK;
	sFilterConfig.FilterScale = CAN_FILTERSCALE_32BIT;
	sFilterConfig.FilterIdHigh = 0x0000;
	sFilterConfig.FilterIdLow = 0x0000;
	sFilterConfig.FilterMaskIdHigh = 0x0000;
	sFilterConfig.FilterMaskIdLow = 0x0000;
	sFilterConfig.FilterFIFOAssignment = CAN_RX_FIFO0;
	sFilterConfig.FilterActivation = ENABLE;
	//sFilterConfig.SlaveStartFilterBank = 14;
	if (HAL_CAN_ConfigFilter(&hcan1, &sFilterConfig) != HAL_OK) {
		/* Filter configuration Error */
		Error_Handler();
	}
	if (HAL_CAN_Start(&hcan1) != HAL_OK) {
		/* Start Error */
		Error_Handler();
	}
	if (HAL_CAN_ActivateNotification(&hcan1, CAN_IT_RX_FIFO0_MSG_PENDING)
			!= HAL_OK) {
		Error_Handler();
	}
	__HAL_RCC_CAN1_CLK_ENABLE();
  /* USER CODE END CAN1_Init 2 */

}

static void MX_CRC_Init(void)
{

  hcrc.Instance = CRC;
  if (HAL_CRC_Init(&hcrc) != HAL_OK)
  {
    Error_Handler();
  }

}

static void MX_DMA2D_Init(void)
{

  hdma2d.Instance = DMA2D;
  hdma2d.Init.Mode = DMA2D_M2M;
  hdma2d.Init.ColorMode = DMA2D_OUTPUT_RGB565;
  hdma2d.Init.OutputOffset = 0;
  hdma2d.LayerCfg[1].InputOffset = 0;
  hdma2d.LayerCfg[1].InputColorMode = DMA2D_INPUT_RGB565;
  hdma2d.LayerCfg[1].AlphaMode = DMA2D_NO_MODIF_ALPHA;
  hdma2d.LayerCfg[1].InputAlpha = 0;
  if (HAL_DMA2D_Init(&hdma2d) != HAL_OK)
  {
    Error_Handler();
  }
  if (HAL_DMA2D_ConfigLayer(&hdma2d, 1) != HAL_OK)
  {
    Error_Handler();
  }

}

static void MX_I2C2_Init(void)
{

  hi2c2.Instance = I2C2;
  hi2c2.Init.ClockSpeed = 400000;
  hi2c2.Init.DutyCycle = I2C_DUTYCYCLE_2;
  hi2c2.Init.OwnAddress1 = 52;
  hi2c2.Init.AddressingMode = I2C_ADDRESSINGMODE_7BIT;
  hi2c2.Init.DualAddressMode = I2C_DUALADDRESS_DISABLE;
  hi2c2.Init.OwnAddress2 = 0;
  hi2c2.Init.GeneralCallMode = I2C_GENERALCALL_DISABLE;
  hi2c2.Init.NoStretchMode = I2C_NOSTRETCH_DISABLE;
  if (HAL_I2C_Init(&hi2c2) != HAL_OK)
  {
    Error_Handler();
  }

  /** Configure Analogue filter
  */
  if (HAL_I2CEx_ConfigAnalogFilter(&hi2c2, I2C_ANALOGFILTER_ENABLE) != HAL_OK)
  {
    Error_Handler();
  }

  /** Configure Digital filter
  */
  if (HAL_I2CEx_ConfigDigitalFilter(&hi2c2, 0) != HAL_OK)
  {
    Error_Handler();
  }

}

static void MX_I2C3_Init(void)
{

  hi2c3.Instance = I2C3;
  hi2c3.Init.ClockSpeed = 100000;
  hi2c3.Init.DutyCycle = I2C_DUTYCYCLE_2;
  hi2c3.Init.OwnAddress1 = 0;
  hi2c3.Init.AddressingMode = I2C_ADDRESSINGMODE_7BIT;
  hi2c3.Init.DualAddressMode = I2C_DUALADDRESS_DISABLE;
  hi2c3.Init.OwnAddress2 = 0;
  hi2c3.Init.GeneralCallMode = I2C_GENERALCALL_DISABLE;
  hi2c3.Init.NoStretchMode = I2C_NOSTRETCH_DISABLE;
  if (HAL_I2C_Init(&hi2c3) != HAL_OK)
  {
    Error_Handler();
  }

  /** Configure Analogue filter
  */
  if (HAL_I2CEx_ConfigAnalogFilter(&hi2c3, I2C_ANALOGFILTER_ENABLE) != HAL_OK)
  {
    Error_Handler();
  }

  /** Configure Digital filter
  */
  if (HAL_I2CEx_ConfigDigitalFilter(&hi2c3, 0) != HAL_OK)
  {
    Error_Handler();
  }

}

static void MX_LTDC_Init(void)
{

  LTDC_LayerCfgTypeDef pLayerCfg = {0};

  hltdc.Instance = LTDC;
  hltdc.Init.HSPolarity = LTDC_HSPOLARITY_AH;
  hltdc.Init.VSPolarity = LTDC_VSPOLARITY_AH;
  hltdc.Init.DEPolarity = LTDC_DEPOLARITY_AL;
  hltdc.Init.PCPolarity = LTDC_PCPOLARITY_IIPC;
  hltdc.Init.HorizontalSync = 5;
  hltdc.Init.VerticalSync = 14;
  hltdc.Init.AccumulatedHBP = 17;
  hltdc.Init.AccumulatedVBP = 44;
  hltdc.Init.AccumulatedActiveW = 497;
  hltdc.Init.AccumulatedActiveH = 1324;
  hltdc.Init.TotalWidth = 509;
  hltdc.Init.TotalHeigh = 1339;
  hltdc.Init.Backcolor.Blue = 0;
  hltdc.Init.Backcolor.Green = 0;
  hltdc.Init.Backcolor.Red = 0;
  if (HAL_LTDC_Init(&hltdc) != HAL_OK)
  {
    Error_Handler();
  }
  pLayerCfg.WindowX0 = 0;
  pLayerCfg.WindowX1 = 480;
  pLayerCfg.WindowY0 = 0;
  pLayerCfg.WindowY1 = 1280;
  pLayerCfg.PixelFormat = LTDC_PIXEL_FORMAT_RGB565;
  pLayerCfg.Alpha = 255;
  pLayerCfg.Alpha0 = 0;
  pLayerCfg.BlendingFactor1 = LTDC_BLENDING_FACTOR1_PAxCA;
  pLayerCfg.BlendingFactor2 = LTDC_BLENDING_FACTOR2_PAxCA;
  pLayerCfg.FBStartAdress = 0xD0000000;
  pLayerCfg.ImageWidth = 480;
  pLayerCfg.ImageHeight = 1280;
  pLayerCfg.Backcolor.Blue = 0;
  pLayerCfg.Backcolor.Green = 0;
  pLayerCfg.Backcolor.Red = 0;
  if (HAL_LTDC_ConfigLayer(&hltdc, &pLayerCfg, 0) != HAL_OK)
  {
    Error_Handler();
  }

}

static void MX_SPI1_Init(void)
{

  /* SPI1 parameter configuration*/
  hspi1.Instance = SPI1;
  hspi1.Init.Mode = SPI_MODE_MASTER;
  hspi1.Init.Direction = SPI_DIRECTION_2LINES;
  hspi1.Init.DataSize = SPI_DATASIZE_8BIT;
  hspi1.Init.CLKPolarity = SPI_POLARITY_LOW;
  hspi1.Init.CLKPhase = SPI_PHASE_1EDGE;
  hspi1.Init.NSS = SPI_NSS_SOFT;
  hspi1.Init.BaudRatePrescaler = SPI_BAUDRATEPRESCALER_8;
  hspi1.Init.FirstBit = SPI_FIRSTBIT_MSB;
  hspi1.Init.TIMode = SPI_TIMODE_DISABLE;
  hspi1.Init.CRCCalculation = SPI_CRCCALCULATION_DISABLE;
  hspi1.Init.CRCPolynomial = 10;
  if (HAL_SPI_Init(&hspi1) != HAL_OK)
  {
    Error_Handler();
  }

}

static void MX_TIM1_Init(void)
{

  TIM_ClockConfigTypeDef sClockSourceConfig = {0};
  TIM_MasterConfigTypeDef sMasterConfig = {0};

  htim1.Instance = TIM1;
  htim1.Init.Prescaler = 0;
  htim1.Init.CounterMode = TIM_COUNTERMODE_UP;
  htim1.Init.Period = 210;
  htim1.Init.ClockDivision = TIM_CLOCKDIVISION_DIV1;
  htim1.Init.RepetitionCounter = 0;
  htim1.Init.AutoReloadPreload = TIM_AUTORELOAD_PRELOAD_DISABLE;
  if (HAL_TIM_Base_Init(&htim1) != HAL_OK)
  {
    Error_Handler();
  }
  sClockSourceConfig.ClockSource = TIM_CLOCKSOURCE_INTERNAL;
  if (HAL_TIM_ConfigClockSource(&htim1, &sClockSourceConfig) != HAL_OK)
  {
    Error_Handler();
  }
  sMasterConfig.MasterOutputTrigger = TIM_TRGO_RESET;
  sMasterConfig.MasterSlaveMode = TIM_MASTERSLAVEMODE_DISABLE;
  if (HAL_TIMEx_MasterConfigSynchronization(&htim1, &sMasterConfig) != HAL_OK)
  {
    Error_Handler();
  }

}

static void MX_TIM13_Init(void)
{

  TIM_OC_InitTypeDef sConfigOC = {0};

  htim13.Instance = TIM13;
  htim13.Init.Prescaler = 90-1;
  htim13.Init.CounterMode = TIM_COUNTERMODE_UP;
  htim13.Init.Period = 1000-1;
  htim13.Init.ClockDivision = TIM_CLOCKDIVISION_DIV1;
  htim13.Init.AutoReloadPreload = TIM_AUTORELOAD_PRELOAD_ENABLE;
  if (HAL_TIM_Base_Init(&htim13) != HAL_OK)
  {
    Error_Handler();
  }
  if (HAL_TIM_PWM_Init(&htim13) != HAL_OK)
  {
    Error_Handler();
  }
  sConfigOC.OCMode = TIM_OCMODE_PWM1;
  sConfigOC.Pulse = 0;
  sConfigOC.OCPolarity = TIM_OCPOLARITY_HIGH;
  sConfigOC.OCFastMode = TIM_OCFAST_DISABLE;
  if (HAL_TIM_PWM_ConfigChannel(&htim13, &sConfigOC, TIM_CHANNEL_1) != HAL_OK)
  {
    Error_Handler();
  }
  HAL_TIM_MspPostInit(&htim13);

}

static void MX_USART1_UART_Init(void)
{

  LL_USART_InitTypeDef USART_InitStruct = {0};

  LL_GPIO_InitTypeDef GPIO_InitStruct = {0};

  /* Peripheral clock enable */
  LL_APB2_GRP1_EnableClock(LL_APB2_GRP1_PERIPH_USART1);

  LL_AHB1_GRP1_EnableClock(LL_AHB1_GRP1_PERIPH_GPIOA);
  /**USART1 GPIO Configuration
  PA9   ------> USART1_TX
  PA10   ------> USART1_RX
  */
  GPIO_InitStruct.Pin = LL_GPIO_PIN_9|LL_GPIO_PIN_10;
  GPIO_InitStruct.Mode = LL_GPIO_MODE_ALTERNATE;
  GPIO_InitStruct.Speed = LL_GPIO_SPEED_FREQ_VERY_HIGH;
  GPIO_InitStruct.OutputType = LL_GPIO_OUTPUT_PUSHPULL;
  GPIO_InitStruct.Pull = LL_GPIO_PULL_NO;
  GPIO_InitStruct.Alternate = LL_GPIO_AF_7;
  LL_GPIO_Init(GPIOA, &GPIO_InitStruct);

  /* USART1 interrupt Init */
  NVIC_SetPriority(USART1_IRQn, NVIC_EncodePriority(NVIC_GetPriorityGrouping(),5, 0));
  NVIC_EnableIRQ(USART1_IRQn);

  USART_InitStruct.BaudRate = 9600;
  USART_InitStruct.DataWidth = LL_USART_DATAWIDTH_8B;
  USART_InitStruct.StopBits = LL_USART_STOPBITS_1;
  USART_InitStruct.Parity = LL_USART_PARITY_NONE;
  USART_InitStruct.TransferDirection = LL_USART_DIRECTION_TX_RX;
  USART_InitStruct.HardwareFlowControl = LL_USART_HWCONTROL_NONE;
  USART_InitStruct.OverSampling = LL_USART_OVERSAMPLING_16;
  LL_USART_Init(USART1, &USART_InitStruct);
  LL_USART_ConfigAsyncMode(USART1);
  LL_USART_Enable(USART1);

}

static void MX_USART3_UART_Init(void)
{

  huart3.Instance = USART3;
  huart3.Init.BaudRate = 115200;
  huart3.Init.WordLength = UART_WORDLENGTH_8B;
  huart3.Init.StopBits = UART_STOPBITS_1;
  huart3.Init.Parity = UART_PARITY_NONE;
  huart3.Init.Mode = UART_MODE_TX_RX;
  huart3.Init.HwFlowCtl = UART_HWCONTROL_NONE;
  huart3.Init.OverSampling = UART_OVERSAMPLING_16;
  if (HAL_UART_Init(&huart3) != HAL_OK)
  {
    Error_Handler();
  }

}

static void MX_DMA_Init(void)
{

  /* DMA controller clock enable */
  __HAL_RCC_DMA1_CLK_ENABLE();

  /* DMA interrupt init */
  /* DMA1_Stream1_IRQn interrupt configuration */
  HAL_NVIC_SetPriority(DMA1_Stream1_IRQn, 5, 0);
  HAL_NVIC_EnableIRQ(DMA1_Stream1_IRQn);
  /* DMA1_Stream3_IRQn interrupt configuration */
  HAL_NVIC_SetPriority(DMA1_Stream3_IRQn, 5, 0);
  HAL_NVIC_EnableIRQ(DMA1_Stream3_IRQn);

}

/* FMC initialization function */
static void MX_FMC_Init(void)
{

  FMC_SDRAM_TimingTypeDef SdramTiming = {0};

  /** Perform the SDRAM1 memory initialization sequence
  */
  hsdram1.Instance = FMC_SDRAM_DEVICE;
  /* hsdram1.Init */
  hsdram1.Init.SDBank = FMC_SDRAM_BANK2;
  hsdram1.Init.ColumnBitsNumber = FMC_SDRAM_COLUMN_BITS_NUM_9;
  hsdram1.Init.RowBitsNumber = FMC_SDRAM_ROW_BITS_NUM_13;
  hsdram1.Init.MemoryDataWidth = FMC_SDRAM_MEM_BUS_WIDTH_16;
  hsdram1.Init.InternalBankNumber = FMC_SDRAM_INTERN_BANKS_NUM_4;
  hsdram1.Init.CASLatency = FMC_SDRAM_CAS_LATENCY_3;
  hsdram1.Init.WriteProtection = FMC_SDRAM_WRITE_PROTECTION_DISABLE;
  hsdram1.Init.SDClockPeriod = FMC_SDRAM_CLOCK_PERIOD_2;
  hsdram1.Init.ReadBurst = FMC_SDRAM_RBURST_ENABLE;
  hsdram1.Init.ReadPipeDelay = FMC_SDRAM_RPIPE_DELAY_1;
  /* SdramTiming */
  SdramTiming.LoadToActiveDelay = 2;
  SdramTiming.ExitSelfRefreshDelay = 8;
  SdramTiming.SelfRefreshTime = 4;
  SdramTiming.RowCycleDelay = 7;
  SdramTiming.WriteRecoveryTime = 5;
  SdramTiming.RPDelay = 2;
  SdramTiming.RCDDelay = 2;

  if (HAL_SDRAM_Init(&hsdram1, &SdramTiming) != HAL_OK)
  {
    Error_Handler( );
  }

  /* USER CODE BEGIN FMC_Init 2 */
	FMC_SDRAM_CommandTypeDef command;
	if (SDRAM_Initialization_Sequence(&hsdram1, &command) != HAL_OK) {
		Error_Handler();
	}
  /* USER CODE END FMC_Init 2 */
}

static void MX_GPIO_Init(void)
{
  GPIO_InitTypeDef GPIO_InitStruct = {0};

  /* GPIO Ports Clock Enable */
  __HAL_RCC_GPIOE_CLK_ENABLE();
  __HAL_RCC_GPIOC_CLK_ENABLE();
  __HAL_RCC_GPIOI_CLK_ENABLE();
  __HAL_RCC_GPIOF_CLK_ENABLE();
  __HAL_RCC_GPIOH_CLK_ENABLE();
  __HAL_RCC_GPIOA_CLK_ENABLE();
  __HAL_RCC_GPIOB_CLK_ENABLE();
  __HAL_RCC_GPIOG_CLK_ENABLE();
  __HAL_RCC_GPIOD_CLK_ENABLE();

  /*Configure GPIO pin Output Level */
  HAL_GPIO_WritePin(GPIOE, LED_CAN2_Pin|LED_CAN1_Pin|LED_ALERT_Pin|LED_ACTIVE_Pin, GPIO_PIN_RESET);

  /*Configure GPIO pin Output Level */
  HAL_GPIO_WritePin(TOUCH_RST_PC13_GPIO_Port, TOUCH_RST_PC13_Pin, GPIO_PIN_SET);

  /*Configure GPIO pin Output Level */
  HAL_GPIO_WritePin(GPIOF, CAN1_S0_Pin|CAN2_S0_Pin, GPIO_PIN_SET);

  /*Configure GPIO pin Output Level */
  HAL_GPIO_WritePin(SD_CS_PIN_GPIO_Port, SD_CS_PIN_Pin, GPIO_PIN_RESET);

  /*Configure GPIO pin Output Level */
  HAL_GPIO_WritePin(GPIOD, IN_S0_Pin|IN_S1_Pin|IN_S2_Pin|PUD_E_Pin, GPIO_PIN_RESET);

  /*Configure GPIO pin Output Level */
  HAL_GPIO_WritePin(GPIOG, IN_E_Pin|OUT_S0_Pin|PUD_S2_Pin|PUD_S1_Pin
                          |PUD_S0_Pin, GPIO_PIN_RESET);

  /*Configure GPIO pin Output Level */
  HAL_GPIO_WritePin(FLASH_CS_GPIO_Port, FLASH_CS_Pin, GPIO_PIN_SET);

  /*Configure GPIO pins : LED_CAN2_Pin LED_CAN1_Pin LED_ALERT_Pin LED_ACTIVE_Pin */
  GPIO_InitStruct.Pin = LED_CAN2_Pin|LED_CAN1_Pin|LED_ALERT_Pin|LED_ACTIVE_Pin;
  GPIO_InitStruct.Mode = GPIO_MODE_OUTPUT_PP;
  GPIO_InitStruct.Pull = GPIO_NOPULL;
  GPIO_InitStruct.Speed = GPIO_SPEED_FREQ_LOW;
  HAL_GPIO_Init(GPIOE, &GPIO_InitStruct);

  /*Configure GPIO pin : TOUCH_RST_PC13_Pin */
  GPIO_InitStruct.Pin = TOUCH_RST_PC13_Pin;
  GPIO_InitStruct.Mode = GPIO_MODE_OUTPUT_PP;
  GPIO_InitStruct.Pull = GPIO_NOPULL;
  GPIO_InitStruct.Speed = GPIO_SPEED_FREQ_LOW;
  HAL_GPIO_Init(TOUCH_RST_PC13_GPIO_Port, &GPIO_InitStruct);

  /*Configure GPIO pin : TOUCH_EN_Pin */
  GPIO_InitStruct.Pin = TOUCH_EN_Pin;
  GPIO_InitStruct.Mode = GPIO_MODE_IT_RISING;
  GPIO_InitStruct.Pull = GPIO_PULLUP;
  HAL_GPIO_Init(TOUCH_EN_GPIO_Port, &GPIO_InitStruct);

  /*Configure GPIO pins : CAN1_S0_Pin CAN2_S0_Pin */
  GPIO_InitStruct.Pin = CAN1_S0_Pin|CAN2_S0_Pin;
  GPIO_InitStruct.Mode = GPIO_MODE_OUTPUT_PP;
  GPIO_InitStruct.Pull = GPIO_PULLUP;
  GPIO_InitStruct.Speed = GPIO_SPEED_FREQ_VERY_HIGH;
  HAL_GPIO_Init(GPIOF, &GPIO_InitStruct);

  /*Configure GPIO pins : HALL_OUT_Pin BTN_2_PC6_Pin BTN_1_PC7_Pin BTN_4_PE5_Pin */
  GPIO_InitStruct.Pin = HALL_OUT_Pin|BTN_2_PC6_Pin|BTN_1_PC7_Pin|BTN_4_PE5_Pin;
  GPIO_InitStruct.Mode = GPIO_MODE_INPUT;
  GPIO_InitStruct.Pull = GPIO_NOPULL;
  HAL_GPIO_Init(GPIOC, &GPIO_InitStruct);

  /*Configure GPIO pins : PB12 PB13 */
  GPIO_InitStruct.Pin = GPIO_PIN_12|GPIO_PIN_13;
  GPIO_InitStruct.Mode = GPIO_MODE_AF_PP;
  GPIO_InitStruct.Pull = GPIO_NOPULL;
  GPIO_InitStruct.Speed = GPIO_SPEED_FREQ_VERY_HIGH;
  GPIO_InitStruct.Alternate = GPIO_AF9_CAN2;
  HAL_GPIO_Init(GPIOB, &GPIO_InitStruct);

  /*Configure GPIO pin : SD_CS_PIN_Pin */
  GPIO_InitStruct.Pin = SD_CS_PIN_Pin;
  GPIO_InitStruct.Mode = GPIO_MODE_OUTPUT_PP;
  GPIO_InitStruct.Pull = GPIO_NOPULL;
  GPIO_InitStruct.Speed = GPIO_SPEED_FREQ_LOW;
  HAL_GPIO_Init(SD_CS_PIN_GPIO_Port, &GPIO_InitStruct);

  /*Configure GPIO pins : PC10 PC11 PC12 */
  GPIO_InitStruct.Pin = GPIO_PIN_10|GPIO_PIN_11|GPIO_PIN_12;
  GPIO_InitStruct.Mode = GPIO_MODE_AF_PP;
  GPIO_InitStruct.Pull = GPIO_NOPULL;
  GPIO_InitStruct.Speed = GPIO_SPEED_FREQ_VERY_HIGH;
  GPIO_InitStruct.Alternate = GPIO_AF6_SPI3;
  HAL_GPIO_Init(GPIOC, &GPIO_InitStruct);

  /*Configure GPIO pins : IN_S0_Pin IN_S1_Pin IN_S2_Pin PUD_E_Pin */
  GPIO_InitStruct.Pin = IN_S0_Pin|IN_S1_Pin|IN_S2_Pin|PUD_E_Pin;
  GPIO_InitStruct.Mode = GPIO_MODE_OUTPUT_PP;
  GPIO_InitStruct.Pull = GPIO_NOPULL;
  GPIO_InitStruct.Speed = GPIO_SPEED_FREQ_LOW;
  HAL_GPIO_Init(GPIOD, &GPIO_InitStruct);

  /*Configure GPIO pins : IN_E_Pin OUT_S0_Pin PUD_S2_Pin PUD_S1_Pin
                           PUD_S0_Pin */
  GPIO_InitStruct.Pin = IN_E_Pin|OUT_S0_Pin|PUD_S2_Pin|PUD_S1_Pin
                          |PUD_S0_Pin;
  GPIO_InitStruct.Mode = GPIO_MODE_OUTPUT_PP;
  GPIO_InitStruct.Pull = GPIO_NOPULL;
  GPIO_InitStruct.Speed = GPIO_SPEED_FREQ_LOW;
  HAL_GPIO_Init(GPIOG, &GPIO_InitStruct);

  /*Configure GPIO pin : FLASH_CS_Pin */
  GPIO_InitStruct.Pin = FLASH_CS_Pin;
  GPIO_InitStruct.Mode = GPIO_MODE_OUTPUT_PP;
  GPIO_InitStruct.Pull = GPIO_NOPULL;
  GPIO_InitStruct.Speed = GPIO_SPEED_FREQ_HIGH;
  HAL_GPIO_Init(FLASH_CS_GPIO_Port, &GPIO_InitStruct);

  /* EXTI interrupt init*/
  HAL_NVIC_SetPriority(EXTI15_10_IRQn, 5, 0);
  HAL_NVIC_EnableIRQ(EXTI15_10_IRQn);

}

/* USER CODE BEGIN 4 */

float mapFloat(float x, float in_min, float in_max, float out_min,
		float out_max) {
	return (x - in_min) * (out_max - out_min) / (in_max - in_min) + out_min;
}

long mapInt(float x, float in_min, float in_max, int out_min, int out_max) {
	return (int) ((x - in_min) * (out_max - out_min) / (in_max - in_min)
			+ out_min);
}

void HAL_GPIO_EXTI_Callback(uint16_t GPIO_Pin)
{
  if(GPIO_Pin == INT_PIN)
  {
	  TOUCH_Set();
  }
}

char* build_status_json(void) {
    cJSON *root = cJSON_CreateObject();
    if (!root) return NULL;

    cJSON_AddStringToObject(root, "type", "update");

    cJSON *payload = cJSON_CreateObject();
    if (!payload) {
        cJSON_Delete(root);
        return NULL;
    }

    // Добавляем поля из структуры, соответствующие вашему примеру JSON
    cJSON_AddNumberToObject(payload, "rpm", Current_Status.RPM);
    cJSON_AddNumberToObject(payload, "map", Current_Status.MAP);
    cJSON_AddNumberToObject(payload, "tps", Current_Status.TPS1);
    cJSON_AddNumberToObject(payload, "afr", Current_Status.AFR);
    cJSON_AddNumberToObject(payload, "IgnTiming", Current_Status.IgnitionTiming);
    cJSON_AddNumberToObject(payload, "motorhours", Current_Status.MOTOHOURS);
    cJSON_AddNumberToObject(payload, "pps", Current_Status.PPS);
    cJSON_AddNumberToObject(payload, "speed", Current_Status.GPS_SPEED);
    cJSON_AddNumberToObject(payload, "clt", Current_Status.CoolantTemp);
    cJSON_AddNumberToObject(payload, "iat", Current_Status.IntakeTemp);
    cJSON_AddNumberToObject(payload, "oilTemp", Current_Status.OilTemperature);
    cJSON_AddNumberToObject(payload, "oilPress", Current_Status.OilPress);
    cJSON_AddNumberToObject(payload, "oilLevel", Current_Status.OilLevel); // В структуре FuelFlow - можно заменить на FuelPress если есть
    cJSON_AddNumberToObject(payload, "fuelLevelraw", Current_Status.FuelLevelRaw);
    cJSON_AddNumberToObject(payload, "knockCt", Current_Status.KnockCt);
    cJSON_AddNumberToObject(payload, "fueluseds", Current_Status.FUELUSEDs);
//    cJSON_AddNumberToObject(payload, "statusFlags", Current_Status.ENGINE_PROTECTION);
//    cJSON_AddNumberToObject(payload, "errorCode", Current_Status.LastError);
    cJSON_AddNumberToObject(payload, "battVolt", Current_Status.BattVolt);
 //   cJSON_AddNumberToObject(payload, "knockLevel", Current_Status.KnockCt);

    cJSON_AddItemToObject(root, "payload", payload);

    char *json_str = cJSON_PrintUnformatted(root);
    cJSON_Delete(root);
    return json_str; // Освободить после использования через free()
}

void InitFlags(void) {
    flags_union.flags.CAN_ABIT = 0;
    flags_union.flags.CAN_RUSEFI = 1;
}

// Глобальная функция обработки сообщений CAN
void HAL_CAN_RxFifo0MsgPendingCallback(CAN_HandleTypeDef *hcan) {
    if (HAL_CAN_GetRxMessage(hcan, CAN_RX_FIFO0, &RxHeader, RxData) != HAL_OK) {
        // Ошибка при получении сообщения CAN
        return;
    }

    // Если CAN не включен, выходим (если нужно)
    // if (!Current_Status.CAN_ENABLED) return;

    // --- Переключение между протоколами ---
    if (flags_union.flags.CAN_RUSEFI && !flags_union.flags.CAN_ABIT) {
        // --- rusefi протокол ---
        switch (RxHeader.StdId) {
            case 3221225472: Handle_BO_3221225472(RxData); break;
            case 512: Handle_BO_512(RxData); break;
            case 513: Handle_BO_513(RxData); break;
            case 514: Handle_BO_514(RxData); break;
            case 515: Handle_BO_515(RxData); break;
            case 516: Handle_BO_516(RxData); break;
            case 517: Handle_BO_517(RxData); break;
            case 518: Handle_BO_518(RxData); break;
            case 519: Handle_BO_519(RxData); break;
            case 520: Handle_BO_520(RxData); break;
            case 521: Handle_BO_521(RxData); break;
            default:
                // Обработка неизвестного ID CAN для rusefi
                break;
        }
    } else if (!flags_union.flags.CAN_RUSEFI && flags_union.flags.CAN_ABIT) {
        // --- ABIT протокол ---
        switch (RxHeader.StdId) {
            case 0x281: Handle_BO_0x281(RxData); break;
            case 0x282: Handle_BO_0x282(RxData); break;
            case 0x283: Handle_BO_0x283(RxData); break;
            case 0x284: Handle_BO_0x284(RxData); break;
            case 0x381: Handle_BO_0x381(RxData); break;
            case 0x382: Handle_BO_0x382(RxData); break;
            case 0x383: Handle_BO_0x383(RxData); break;
            case 0x481: Handle_BO_0x481(RxData); break;
            case 0x482: Handle_BO_0x482(RxData); break;
            case 0x581: Handle_BO_0x581(RxData); break;
            case 0x582: Handle_BO_0x582(RxData); break;
            case 0x583: Handle_BO_0x583(RxData); break;
            case 0x584: Handle_BO_0x584(RxData); break;
            case 0x781: Handle_BO_0x781(RxData); break;
//            case 0x211: Handle_BO_0x211(RxData); break;
//            case 0x212: Handle_BO_0x212(RxData); break;
//            case 0x511: Handle_BO_0x511(RxData); break;
//            case 0x512: Handle_BO_0x512(RxData); break;
//            case 0x385: Handle_BO_0x385(RxData); break;
//            case 0x784: Handle_BO_0x784(RxData); break;
            default:
                // Обработка неизвестного ID CAN для ABIT
                break;
        }
    } else {
        // Некорректная конфигурация протоколов (оба флага или ни одного)
        // Можно добавить логирование или аварийную индикацию
    }

    // --- Обработка ошибок ---

 /*   if (Current_Status.LastError != 0) {
        Current_Status.IND_DTC = true;
        Current_Status.Error_Mes = Error_code(Current_Status.LastError);
        Current_Status.container1 = true;
    } else {
        Current_Status.container1 = false;
        Current_Status.IND_DTC = false;
    }*/
}

 // оброботчик прерываний прием передача USART3

void json_rx_callback(const char* json_str)
{
    if (!json_str) return;
    // Кладём строку в очередь для задачи
    osMessageQueuePut(jsonQueueHandle, json_str, 0, 0);
}

void HAL_UARTEx_RxEventCallback(UART_HandleTypeDef *huart, uint16_t Size) {
    USART3_JSON_RxEventCallback(huart, Size);
}

void HAL_UART_TxCpltCallback(UART_HandleTypeDef *huart) {
     USART3_JSON_TxCpltCallback(huart);
}

void app_init_usart3(void)
{
    USART3_JSON_Init(&huart3, 115200, json_rx_callback);
}

void initAll(void) {

	Current_Status.LCD_BRIGHTNESS = LCD_DEFAULT_BRIGHTNESS;
	Current_Status.LCD_BRIGHTNESS_CHANGED = 1;
	htim13.Instance->CCR1 = Current_Status.LCD_BRIGHTNESS;

	Current_Status.CAN_ENABLED = 0;

	HAL_TIM_PWM_Start(&htim13, TIM_CHANNEL_1);

//	LoadFlagsFromEEPROM();

}
//  сохронение флагов в епром
void SaveFlagsToEEPROM(void) {
    flags_union.flags = device_flags; // Копируем структуру в union
    EEPROM_WriteFlags(flags_union.raw);

}

// чтение флагов в епром
	bool LoadFlagsFromEEPROM(void) {
	    if (EEPROM_ReadDual(eeprom_cfg.flags_main_addr, eeprom_cfg.flags_backup_addr, &flags_union.raw, sizeof(flags_union.raw))) {
	        device_flags = flags_union.flags; // Копируем обратно в структуру
	        return true;
	    }
	    return false;
	}

// Среднее скользящее

typedef struct {
    float *values;  // Указатель на массив значений
    int index;
    int count;
    int windowSize; // Размер окна
} MovingAverage;

// Функция инициализации скользящего среднего
void initMovingAverage(MovingAverage *ma, int windowSize) {
    ma->windowSize = windowSize;
    ma->index = 0;
    ma->count = 0;
    ma->values = (float *)malloc(windowSize * sizeof(float)); // Динамическое выделение памяти

    for (int i = 0; i < windowSize; i++) {
        ma->values[i] = 0.0f;
    }
}

// Функция освобождения ресурсов
void freeMovingAverage(MovingAverage *ma) {
    free(ma->values); // Освобождение выделенной памяти
}

// Функция обновления скользящего среднего
float updateMovingAverage(MovingAverage *ma, float newValue) {
    ma->values[ma->index] = newValue;
    ma->index = (ma->index + 1) % ma->windowSize;

    if (ma->count < ma->windowSize) {
        ma->count++;
    }

    float sum = 0.0f;
    for (int i = 0; i < ma->count; i++) {
        sum += ma->values[i];
    }

    return sum / ma->count; // Возврат SMA
}

// округление до кратного

int roundToNearest(int value, int multiple) {
    // Находим остаток от деления на кратное значение
    int remainder = value % multiple;

    // Если остаток меньше половины от кратного значения, округляем вниз
    // Иначе округляем вверх
    if (remainder < multiple / 2) {
        return value - remainder; // Округляем вниз
    } else {
        return value + (multiple - remainder); // Округляем вверх
    }
}

/* USER CODE END 4 */

void Start_START_Task(void *argument)
{
  /* init code for USB_DEVICE */
  MX_USB_DEVICE_Init();
  /* USER CODE BEGIN 5 */
	osDelay(250);

	Current_Status.RPM = 0;
	Current_Status.CAN_ENABLED = 1;
	Current_Status.FuelUsed = 0;

	fuel_level_load_table();
	oil_level_load_table();

	for (;;) {

		float raw_fuel = Current_Status.FuelLevelRaw;
	    Current_Status.FuelLevel = fuel_level_get_liters(raw_fuel);
	    Current_Status.FuelLevelGui =  (100/fuelLevelMax)*Current_Status.FuelLevel;
       osDelay(10);
	}

  /* USER CODE END 5 */
}

__weak void TouchGFX_Task(void *argument)
{
  /* USER CODE BEGIN TouchGFX_Task */
//	MX_TouchGFX_Process();

	/* Infinite loop */
	for (;;) {
		osDelay(1);
	}
  /* USER CODE END TouchGFX_Task */
}

void Start_BRIGHTNESS_Task(void *argument)
{
  /* USER CODE BEGIN Start_BRIGHTNESS_Task */
  /* Infinite loop */
  for(;;)
  {
	  if(Current_Status.LCD_BRIGHTNESS > 1000){
	  	 Current_Status.LCD_BRIGHTNESS = 300;
	     }
	  htim13.Instance->CCR1 = Current_Status.LCD_BRIGHTNESS;
	  Current_Status.LCD_BRIGHTNESS_CHANGED = 0;
    osDelay(1);
  }
  /* USER CODE END Start_BRIGHTNESS_Task */
}

void Start_nmea(void *argument)
{
  /* USER CODE BEGIN Start_nmea */
  /* Infinite loop */
	nmea_init(&gps, USART1, 1024);
	  for(;;)
	  {
	    nmea_loop(&gps);
	    osDelay(100);
	  }
  /* USER CODE END Start_nmea */
}

void Start_OIL(void *argument)
{
  /* USER CODE BEGIN Start_OIL */
	ADC_ChannelConfTypeDef sConfig = {0};
	  sConfig.Channel = ADC_CHANNEL_11;
	  sConfig.Rank = 1;
	  sConfig.SamplingTime = ADC_SAMPLETIME_3CYCLES;
  /* Infinite loop */
  for(;;)
  {

	  		if (HAL_ADC_ConfigChannel(&hadc1, &sConfig) != HAL_OK) {
	  			Error_Handler();
	  		}

	  		uint32_t ADCValue = 0;
	  		HAL_ADC_Start(&hadc1);
	  		HAL_ADC_PollForConversion(&hadc1, 1000);
	  		ADCValue = HAL_ADC_GetValue(&hadc1);
	  		HAL_ADC_Stop(&hadc1);
	  		Current_Status.IND_OIL = (ADCValue * 749) * (3.3 / 4096.0);

	  		Current_Status.IND_OIL = Current_Status.IND_OIL < 100 ? true : false;

	  //		Current_Status.IND_DTC = (Current_Status.WarningCounter != 0) ? true : false;
    osDelay(500);
  }
  /* USER CODE END Start_OIL */
}

void Start_Ind_FUEL(void *argument)
{
  /* USER CODE BEGIN Start_Ind_FUEL */
  /* Infinite loop */
  for(;;)
  {
	  uint8_t fuelLevelPercentage = Current_Status.FuelLevel ;

	  if (fuelLevelPercentage < 5) {
	       Current_Status.IND_FUEL = true;
	       osDelay(300);
	       Current_Status.IND_FUEL = false;
	       osDelay(300);
	     } else if (fuelLevelPercentage < 8) {
	       Current_Status.IND_FUEL = true;
	     } else {
	       Current_Status.IND_FUEL = false;
	     }
    osDelay(10);
  }
  /* USER CODE END Start_Ind_FUEL */
}

void Start_IndBATT(void *argument)
{
  /* USER CODE BEGIN Start_IndBATT */
  /* Infinite loop */
  for(;;)
  {

	  float batteryLevel = Current_Status.BattVolt ;

	     if (batteryLevel < 11) {
	        Current_Status.IND_BATT = true;
	        osDelay(300);
	        Current_Status.IND_BATT = false;
	        osDelay(300);
	      } else {
	        Current_Status.IND_BATT = false;
	      }
    osDelay(10);
  }
  /* USER CODE END Start_IndBATT */
}

void Start_Ind_ECT(void *argument)
{
  /* USER CODE BEGIN Start_Ind_ECT */
  /* Infinite loop */
  for(;;)
  {
	  float ect_temp = Current_Status.CoolantTemp / 10.0f; // Вычисляем один раз

	  	  // Индикатор синего цвета
	  	  Current_Status.IND_ECT_BLUE = (ect_temp < 50);

	  	  // Индикатор перегрева (мигание)
	  	  if (ect_temp > 115) {
	  		  Current_Status.IND_ECT = true;
	  		  osDelay(300);
	  		  Current_Status.IND_ECT = false;
	  		  osDelay(300);
	  	  } else {
	  		  Current_Status.IND_ECT = false;
	  	  }
    osDelay(10);
  }
  /* USER CODE END Start_Ind_ECT */
}

void Start_other(void *argument)
{
  /* USER CODE BEGIN Start_other */
  /* Infinite loop */
	float speed_kph = 0;

	  for(;;)
	  {
	    if (nmea_available(&gps))
	    {
	      nmea_gnss_speed_kph(&gps,&speed_kph);
	      Current_Status.GPS_SPEED = speed_kph;
	      nmea_available_reset(&gps);
	   }

	    osDelay(100);
	  }
  /* USER CODE END Start_other */
}

void Start_RMP_10(void *argument)
{
  /* USER CODE BEGIN Start_RMP_10 */
	    int windowSize = *((int *)argument);
	    MovingAverage rpmMA;
	    initMovingAverage(&rpmMA, windowSize);
	    /* Infinite loop */
	    for(;;)
	    {
	        float rpmValue = Current_Status.RPM; // Получение текущего значения RPM
	        float avgRPM = updateMovingAverage(&rpmMA, rpmValue);

	        Current_Status.RPMs = roundToNearest(avgRPM, 25); //   ближайшего значения кратного 25
	        osDelay(50);
	    }
	    freeMovingAverage(&rpmMA); // Освобождение памяти при завершении задачи (если вы используете динамическое выделение)

  /* USER CODE END Start_RMP_10 */
}

void Start_FUELUSED_11(void *argument)
{
  /* USER CODE BEGIN Start_FUELUSED_11 */
	int *windows = (int *)argument;
	int fuelWindow = windows[0];
	int remainsWindow = windows[1];

	MovingAverage fuelUserMA, remainsMA;
	initMovingAverage(&fuelUserMA, fuelWindow);    // Для FuelUsed
	initMovingAverage(&remainsMA, remainsWindow);  // Для RemainsKm

  /* Infinite loop */
  for(;;)
  {
	  // Получаем актуальные значения!
	          float fuel_left_liters = Current_Status.FuelLevel;   // Остаток топлива, литров
	          float avg_consumption_lph = Current_Status.FUELUSEDs; // Средний расход, л/ч
	          float speed_kmh = Current_Status.GPS_SPEED;          // Скорость, км/ч
//	          float remains_km1 = 0 ;
	          // Обновление FuelUsed
	                  float fuelValue = Current_Status.FuelFlow;
	                  Current_Status.FUELUSEDs = updateMovingAverage(&fuelUserMA, fuelValue) + 0.0001f;

	                  // --- Защита от деления на ноль и некорректных значений ---
	                  float raw_remains = 0.0f;
	                  if (avg_consumption_lph > 0.01f && speed_kmh > 0.1f && fuel_left_liters > 0.01f) {
	                      raw_remains = (fuel_left_liters * speed_kmh) / avg_consumption_lph;
	                  } else {
	                      raw_remains = 0.0f; // если расход или скорость слишком малы, запас хода не считаем
	                  }
	                  Current_Status.remains_km = updateMovingAverage(&remainsMA, raw_remains);

	                  // Для отображения целого значения (например, на дисплее)
//	                  Current_Status.remains_km_int = (int)(Current_Status.remains_km + 0.5f);

	              }

	              freeMovingAverage(&fuelUserMA);
	              freeMovingAverage(&remainsMA);

	              osDelay(100);
  /* USER CODE END Start_FUELUSED_11 */
}

void Start_UART_Task(void *argument)
{
  /* USER CODE BEGIN Start_UART_Task */

  /* Infinite loop */
  for(;;){
	  // Формируем JSON-строку (build_status_json должен возвращать malloc-строку!)
/*	  char* json_str = build_data_json(1, 16, fuelLevelTable);
	  if (json_str)
	  {
	      // Ждём, пока UART не освободится (максимум 100 попыток по 1 мс)
	      uint32_t try_cnt = 0;
	      while (USART3_JSON_IsTxBusy())
	      {
	          osDelay(1);
	          if (++try_cnt > 100)
	          {
	              // UART завис? Освобождаем память и выходим из цикла
	              free(json_str);
	              json_str = NULL;
	              break;
	          }
	      }
	      if (json_str)
	      {
	          if (USART3_JSON_Send(json_str) == HAL_OK)
	          {
	              // Можно добавить логирование успеха
	          }
	          else
	          {
	              // Ошибка отправки, можно залогировать
	          }
	          free(json_str);
	      }
	  }*/

	        osDelay(200); // Пауза между отправками (200 мс)
	    }
  /* USER CODE END Start_UART_Task */
}

void Start_MotohoursTask(void *argument)
{
  /* USER CODE BEGIN Start_MotohoursTask */
	 osDelay(100);
	    if (!EEPROM_ReadMotohours(&Current_Status.MOTOHOURS)) {
	        Current_Status.MOTOHOURS = 0;
	    }
	    uint32_t last_saved = Current_Status.MOTOHOURS;
	    const uint32_t SAVE_INTERVAL = 240; // сохранять раз в минуту
  /* Infinite loop */
  for(;;)
  {
	  osDelay(1000);
	  if (Current_Status.RPM > 100)
	  {// 1 секунда
	  Current_Status.MOTOHOURS++;
	  // Сохраняем только если прошло SAVE_INTERVAL секунд
	   if ((Current_Status.MOTOHOURS - last_saved) >= SAVE_INTERVAL) {
	       if (EEPROM_WriteMotohours(Current_Status.MOTOHOURS) == HAL_OK) {
	           eeprom_wait_ready(); // обязательно дождаться окончания записи!
	           }   last_saved = Current_Status.MOTOHOURS;
	      }
	}
  }
  /* USER CODE END Start_MotohoursTask */
}

void Start_R_Buttan_Task14(void *argument)
{
  /* USER CODE BEGIN Start_R_Buttan_Task14 */
  for(;;)
  {
    // Более безопасная проверка с использованием else-if
	  if(Current_Status.RPM < (RPM_THRESHOLD - RPM_HYSTERESIS))
    {
        Current_Status.container4 = false;
        Current_Status.container6 = true;
    }
    else if(Current_Status.RPM > (RPM_THRESHOLD + RPM_HYSTERESIS))// RPM >= 500
    {
    	osDelay(5000);
        Current_Status.container4 = true;
        Current_Status.container6 = false;
    }

    osDelay(1);
  }
  /* USER CODE END Start_R_Buttan_Task14 */
}

void Start_Buttan_L_Task(void *argument)
{
  for(;;)
  {
    osDelay(1);
  }
}

void Start_JSON_Parse_Task(void *argument)
{
  /* USER CODE BEGIN Start_JSON_Parse_Task */

   JsonMessage msg;
  /* Infinite loop */
  for(;;)
  {

  	  /// Получаем строку JSON из очереди (блокирующий вызов)
      if (osMessageQueueGet(jsonQueueHandle, json_buf, NULL, osWaitForever) == osOK)
      {
          memset(&msg, 0, sizeof(msg));
          if (parse_and_dispatch_json(json_buf, &msg))
          {
              switch (msg.type)
              {
                  case JSON_TYPE_COMMAND:
                      handle_command(&msg.payload.command);
                      break;
                  case JSON_TYPE_UPDATE:
                      // handle_status_update(&msg.payload.status);
                      break;
                  case JSON_TYPE_FLAGS:
                      // handle_flags_update(&msg.payload.flags);
                      break;
                  case JSON_TYPE_DATA:
                      handle_data(&msg.payload.data);
                      break;
                  case JSON_TYPE_REQUEST:
                      // handle_request(&msg.payload.request);
                      break;
                  default:
                      // Логировать неизвестный тип
                      break;
              }
          }
          else
          {
              // Логировать ошибку парсинга
          }
     }
osDelay(1);
  }
  /* USER CODE END Start_JSON_Parse_Task */
}

void HAL_TIM_PeriodElapsedCallback(TIM_HandleTypeDef *htim)
{
  if (htim->Instance == TIM6)
  {
    HAL_IncTick();
  }
}

void Error_Handler(void)
{
	__disable_irq();
	while (1) {
	}
}
